VERSION "10.7.1"

NS_ :

BS_:

BU_: ADAS_Chassis AVAS DUMMY_ECU EPS IDB_Chassis MRGEN RCU_Chassis SCAM SRR VCU_Chassis XGW_Chassis YSS

BO_ 1039 YSS_WarnMsg: 8 YSS
 SG_ CHSKM_YSS_WarnMsg : 7|8@0+ (1,0) [0|255] ""  XGW_Chassis
 SG_ ALV_YSS_WarnMsg : 11|4@0+ (1,0) [0|14] ""  XGW_Chassis
 SG_ YSS_Warning_Flag_1 : 12|1@0+ (1,0) [0|1] ""  XGW_Chassis
 SG_ YSS_Warning_Flag_2 : 13|1@0+ (1,0) [0|1] ""  XGW_Chassis
 SG_ YSS_Warning_Flag_3 : 14|1@0+ (1,0) [0|1] ""  XGW_Chassis
 SG_ YSS_Warning_Flag_4 : 15|1@0+ (1,0) [0|1] ""  XGW_Chassis
 SG_ YSS_Warning_Flag_5 : 16|1@0+ (1,0) [0|1] ""  XGW_Chassis
 SG_ YSS_Warning_Flag_6 : 17|1@0+ (1,0) [0|1] ""  XGW_Chassis
 SG_ YSS_Warning_Flag_7 : 18|1@0+ (1,0) [0|1] ""  XGW_Chassis
 SG_ YSS_Warning_Flag_8 : 19|1@0+ (1,0) [0|1] ""  XGW_Chassis
 SG_ YSS_Warning_Flag_9 : 20|1@0+ (1,0) [0|1] ""  XGW_Chassis
 SG_ YSS_Warning_Flag_10 : 21|1@0+ (1,0) [0|1] ""  XGW_Chassis
 SG_ YSS_Warning_Flag_11 : 22|1@0+ (1,0) [0|1] ""  XGW_Chassis
 SG_ YSS_Warning_Flag_12 : 23|1@0+ (1,0) [0|1] ""  XGW_Chassis
 SG_ YSS_Reserved_signal1 : 31|8@0+ (1,0) [0|255] ""  XGW_Chassis
 SG_ YSS_Reserved_signal2 : 39|8@0+ (1,0) [0|255] ""  XGW_Chassis
 SG_ YSS_Reserved_signal3 : 47|8@0+ (1,0) [0|255] ""  XGW_Chassis
 SG_ YSS_Reserved_signal4 : 55|8@0+ (1,0) [0|255] ""  XGW_Chassis
 SG_ YSS_Reserved_signal5 : 63|8@0+ (1,0) [0|255] ""  XGW_Chassis

BO_ 1059 AVAS_STATUS: 8 AVAS
 SG_ AVAS_BatteryUnderVoltage : 0|1@0+ (1,0) [0|1] "-"  VCU_Chassis,XGW_Chassis
 SG_ AVAS_BatteryOverVoltage : 1|1@0+ (1,0) [0|1] "-"  VCU_Chassis,XGW_Chassis
 SG_ AVAS_VINInfoNotPrgm : 2|1@0+ (1,0) [0|1] ""  VCU_Chassis,XGW_Chassis
 SG_ AVAS_AMPVoltSplDrvOperationFail : 3|1@0+ (1,0) [0|1] "-"  VCU_Chassis,XGW_Chassis
 SG_ AVAS_AMPIntFaultOverCurr : 4|1@0+ (1,0) [0|1] ""  VCU_Chassis,XGW_Chassis
 SG_ AVAS_AMPInternalFaultDCError : 5|1@0+ (1,0) [0|1] ""  VCU_Chassis,XGW_Chassis
 SG_ AVAS_AMPInternalFaultOverTemp : 6|1@0+ (1,0) [0|1] ""  VCU_Chassis,XGW_Chassis
 SG_ AVAS_AMPInternalFaultClockError : 7|1@0+ (1,0) [0|1] "-"  VCU_Chassis,XGW_Chassis
 SG_ AVAS_SpkrMntPwrSwDrvHighFlt : 8|1@0+ (1,0) [0|1] "-"  VCU_Chassis,XGW_Chassis
 SG_ AVAS_SpkrMntPwrSwDrvLowFlt : 9|1@0+ (1,0) [0|1] "-"  VCU_Chassis,XGW_Chassis
 SG_ AVAS_InternalSpeakerOpen : 10|1@0+ (1,0) [0|1] ""  VCU_Chassis,XGW_Chassis
 SG_ AVAS_ECUMalFlshOperationErr : 11|1@0+ (1,0) [0|1] ""  VCU_Chassis,XGW_Chassis
 SG_ AVAS_ECUMalfunctionRamFailure : 12|1@0+ (1,0) [0|1] "-"  VCU_Chassis,XGW_Chassis
 SG_ AVAS_ECUMalEEPROMFailure : 13|1@0+ (1,0) [0|1] ""  VCU_Chassis,XGW_Chassis
 SG_ AVAS_CANBusOff : 14|1@0+ (1,0) [0|1] "-"  VCU_Chassis,XGW_Chassis
 SG_ AVAS_LossCommVehicleSpeed : 15|1@0+ (1,0) [0|1] ""  VCU_Chassis,XGW_Chassis
 SG_ AVAS_LossCommGearPosition : 16|1@0+ (1,0) [0|1] "-"  VCU_Chassis,XGW_Chassis
 SG_ AVAS_LossCommAVASCloseCmd : 17|1@0+ (1,0) [0|1] "-"  VCU_Chassis,XGW_Chassis

BO_ 1060 AVAS_SHMNumber: 8 AVAS
 SG_ AVAS_SWNumber : 7|16@0+ (1,0) [0|65535] ""  VCU_Chassis
 SG_ AVAS_HWNumber : 23|16@0+ (1,0) [0|65535] ""  VCU_Chassis
 SG_ AVAS_MXNumber : 39|16@0+ (1,0) [0|65535] ""  VCU_Chassis

BO_ 1061 VCU_AVAS_GearPosition_ECU: 8 VCU_Chassis
 SG_ ActualGearShiftPosition : 50|3@0+ (1,0) [0|7] ""  AVAS,EPS

BO_ 1062 VCU_AVAS_VehicleSpeed_ECU: 8 VCU_Chassis
 SG_ ESP_VehicleSpeed : 4|13@0+ (0.05625,0) [0|460.6875] "kph"  AVAS
 SG_ VCU_STAT_Terminal_BEV : 23|3@0+ (1,0) [0|7] ""  AVAS

BO_ 1063 VCU_AVAS_Close_Cmd: 8 VCU_Chassis
 SG_ IPC_AVASCloseCmd : 0|1@0+ (1,0) [0|1] ""  AVAS

BO_ 1064 XGW_CH_1: 1 XGW_Chassis
 SG_ BCM_Keyfob_Leftcar : 0|1@0+ (1,0) [0|1] ""  VCU_Chassis
 SG_ TRMFitted : 2|2@0+ (1,0) [0|3] ""  ADAS_Chassis

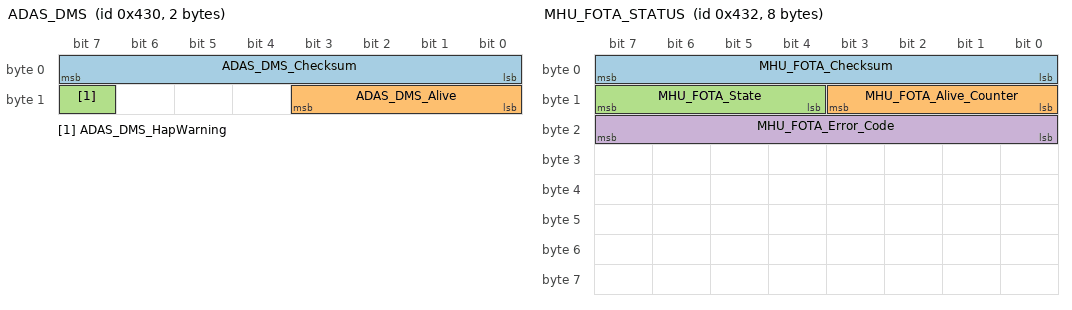
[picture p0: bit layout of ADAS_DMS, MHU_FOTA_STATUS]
BO_ 1072 ADAS_DMS: 2 ADAS_Chassis
 SG_ ADAS_DMS_Checksum : 7|8@0+ (1,0) [0|255] ""  EPS
 SG_ ADAS_DMS_Alive : 11|4@0+ (1,0) [0|14] ""  EPS
 SG_ ADAS_DMS_HapWarning : 15|1@0+ (1,0) [0|1] ""  EPS

BO_ 1074 MHU_FOTA_STATUS: 8 XGW_Chassis
 SG_ MHU_FOTA_Checksum : 7|8@0+ (1,0) [0|255] ""  ADAS_Chassis,EPS,MRGEN,SCAM,SRR
 SG_ MHU_FOTA_Alive_Counter : 11|4@0+ (1,0) [0|14] ""  ADAS_Chassis,EPS,MRGEN,SCAM,SRR
 SG_ MHU_FOTA_State : 15|4@0+ (1,0) [0|14] "-"  ADAS_Chassis,EPS,MRGEN,SCAM,SRR
 SG_ MHU_FOTA_Error_Code : 23|8@0+ (1,0) [0|255] "-"  ADAS_Chassis,EPS,MRGEN,SCAM,SRR

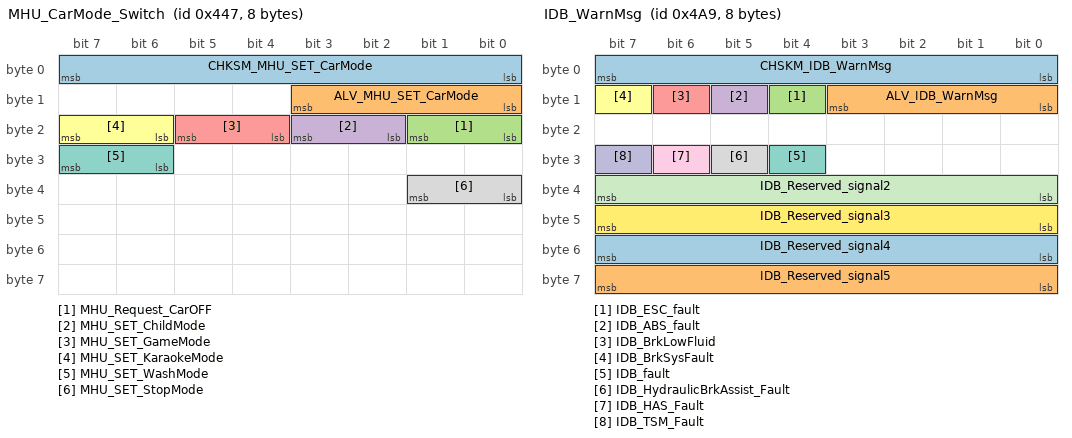
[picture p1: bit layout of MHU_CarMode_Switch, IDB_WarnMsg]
BO_ 1095 MHU_CarMode_Switch: 8 XGW_Chassis
 SG_ CHKSM_MHU_SET_CarMode : 7|8@0+ (1,0) [0|255] ""  IDB_Chassis,RCU_Chassis
 SG_ ALV_MHU_SET_CarMode : 11|4@0+ (1,0) [0|14] ""  IDB_Chassis,RCU_Chassis
 SG_ MHU_Request_CarOFF : 17|2@0+ (1,0) [0|3] "-"  IDB_Chassis,RCU_Chassis
 SG_ MHU_SET_ChildMode : 19|2@0+ (1,0) [0|3] ""  IDB_Chassis,RCU_Chassis
 SG_ MHU_SET_GameMode : 21|2@0+ (1,0) [0|3] ""  IDB_Chassis,RCU_Chassis
 SG_ MHU_SET_KaraokeMode : 23|2@0+ (1,0) [0|3] ""  IDB_Chassis,RCU_Chassis
 SG_ MHU_SET_WashMode : 31|2@0+ (1,0) [0|3] ""  IDB_Chassis,RCU_Chassis
 SG_ MHU_SET_StopMode : 33|2@0+ (1,0) [0|3] ""  IDB_Chassis,RCU_Chassis

BO_ 1191 RCU_WarnMsg: 8 RCU_Chassis
 SG_ CHSKM_RCU_WarnMsg : 7|8@0+ (1,0) [0|255] ""  XGW_Chassis
 SG_ ALV_RCU_WarnMsg : 11|4@0+ (1,0) [0|14] ""  XGW_Chassis
 SG_ RCU_DAA_NoOpDoorOpen : 12|1@0+ (1,0) [0|1] ""  XGW_Chassis
 SG_ RCU_EHandBrk_fault : 13|1@0+ (1,0) [0|1] ""  XGW_Chassis
 SG_ RCU_EOL_NotDone : 14|1@0+ (1,0) [0|1] ""  XGW_Chassis
 SG_ RCU_ECD_RWU_active : 15|1@0+ (1,0) [0|1] ""  XGW_Chassis
 SG_ RCU_ParkOnSteepInclination : 16|1@0+ (1,0) [0|1] ""  XGW_Chassis
 SG_ RCU_BrkForceNotEnough : 17|1@0+ (1,0) [0|1] ""  XGW_Chassis
 SG_ RCU_ReleaseEPB_Wo_PressBrk : 20|1@0+ (1,0) [0|1] ""  XGW_Chassis
 SG_ RCU_ParkBrkApplied : 21|1@0+ (1,0) [0|1] ""  XGW_Chassis
 SG_ RCU_Swch_Mafnc : 27|1@0+ (1,0) [0|1] ""  XGW_Chassis
 SG_ RCU_DAA_NoOpBeltUnbuckled : 28|1@0+ (1,0) [0|1] ""  XGW_Chassis
 SG_ RCU_RollerBenchMode : 29|1@0+ (1,0) [0|1] ""  XGW_Chassis
 SG_ RCU_EPB_ParkLampState : 31|2@0+ (1,0) [0|3] ""  XGW_Chassis
 SG_ RCU_EPB_WarnLampState : 34|2@0+ (1,0) [0|3] ""  XGW_Chassis
 SG_ RCU_WflagRes36 : 36|1@0+ (1,0) [0|1] ""  XGW_Chassis
 SG_ RCU_WflagRes37 : 37|1@0+ (1,0) [0|1] ""  XGW_Chassis
 SG_ RCU_WflagRes38 : 38|1@0+ (1,0) [0|1] ""  XGW_Chassis
 SG_ RCU_WflagRes39 : 39|1@0+ (1,0) [0|1] ""  XGW_Chassis
 SG_ RCU_WflagRes40 : 40|1@0+ (1,0) [0|1] ""  XGW_Chassis
 SG_ RCU_WflagRes41 : 41|1@0+ (1,0) [0|1] ""  XGW_Chassis
 SG_ RCU_WflagRes42 : 42|1@0+ (1,0) [0|1] ""  XGW_Chassis
 SG_ RCU_WflagRes43 : 43|1@0+ (1,0) [0|1] ""  XGW_Chassis
 SG_ RCU_WflagRes44 : 44|1@0+ (1,0) [0|1] ""  XGW_Chassis
 SG_ RCU_WflagRes45 : 45|1@0+ (1,0) [0|1] ""  XGW_Chassis
 SG_ RCU_WflagRes46 : 46|1@0+ (1,0) [0|1] ""  XGW_Chassis
 SG_ RCU_WflagRes47 : 47|1@0+ (1,0) [0|1] ""  XGW_Chassis
 SG_ RCU_Reserved_signal1 : 55|8@0+ (1,0) [0|255] ""  XGW_Chassis

BO_ 1192 EPS_WarnMsg: 8 EPS
 SG_ CHSKM_EPS_WarnMsg : 7|8@0+ (1,0) [0|255] ""  XGW_Chassis
 SG_ ALV_EPS_WarnMsg : 11|4@0+ (1,0) [0|14] ""  XGW_Chassis
 SG_ EPS_Malfunction : 12|1@0+ (1,0) [0|1] "-"  XGW_Chassis
 SG_ EPS_Reduced : 13|1@0+ (1,0) [0|1] "-"  XGW_Chassis
 SG_ EPS_Overheat : 14|1@0+ (1,0) [0|1] ""  XGW_Chassis
 SG_ EPS_NotReady : 15|1@0+ (1,0) [0|1] "-"  XGW_Chassis
 SG_ EPS_Warning_Flag_5 : 16|1@0+ (1,0) [0|1] "-"  XGW_Chassis
 SG_ EPS_Warning_Flag_6 : 17|1@0+ (1,0) [0|1] ""  XGW_Chassis
 SG_ EPS_Warning_Flag_7 : 18|1@0+ (1,0) [0|1] ""  XGW_Chassis
 SG_ EPS_Warning_Flag_8 : 19|1@0+ (1,0) [0|1] "-"  XGW_Chassis
 SG_ EPS_Warning_Flag_9 : 20|1@0+ (1,0) [0|1] "-"  XGW_Chassis
 SG_ EPS_Warning_Flag_10 : 21|1@0+ (1,0) [0|1] ""  XGW_Chassis
 SG_ EPS_Warning_Flag_11 : 22|1@0+ (1,0) [0|1] ""  XGW_Chassis
 SG_ EPS_Warning_Flag_12 : 23|1@0+ (1,0) [0|1] "-"  XGW_Chassis
 SG_ EPS_Reserved_signal1 : 31|8@0+ (1,0) [0|255] ""  XGW_Chassis
 SG_ EPS_Reserved_signal2 : 39|8@0+ (1,0) [0|255] ""  XGW_Chassis
 SG_ EPS_Reserved_signal3 : 47|8@0+ (1,0) [0|255] "-"  XGW_Chassis
 SG_ EPS_Reserved_signal4 : 55|8@0+ (1,0) [0|255] ""  XGW_Chassis
 SG_ EPS_Reserved_signal5 : 63|8@0+ (1,0) [0|255] ""  XGW_Chassis

BO_ 1193 IDB_WarnMsg: 8 IDB_Chassis
 SG_ CHSKM_IDB_WarnMsg : 7|8@0+ (1,0) [0|255] ""  XGW_Chassis
 SG_ ALV_IDB_WarnMsg : 11|4@0+ (1,0) [0|14] ""  XGW_Chassis
 SG_ IDB_ESC_fault : 12|1@0+ (1,0) [0|1] "-"  XGW_Chassis
 SG_ IDB_ABS_fault : 13|1@0+ (1,0) [0|1] ""  XGW_Chassis
 SG_ IDB_BrkLowFluid : 14|1@0+ (1,0) [0|1] ""  XGW_Chassis
 SG_ IDB_BrkSysFault : 15|1@0+ (1,0) [0|1] "-"  XGW_Chassis
 SG_ IDB_fault : 28|1@0+ (1,0) [0|1] ""  SCAM,XGW_Chassis
 SG_ IDB_HydraulicBrkAssist_Fault : 29|1@0+ (1,0) [0|1] "-"  XGW_Chassis
 SG_ IDB_HAS_Fault : 30|1@0+ (1,0) [0|1] ""  XGW_Chassis
 SG_ IDB_TSM_Fault : 31|1@0+ (1,0) [0|1] ""  XGW_Chassis
 SG_ IDB_Reserved_signal2 : 39|8@0+ (1,0) [0|255] "-"  XGW_Chassis
 SG_ IDB_Reserved_signal3 : 47|8@0+ (1,0) [0|255] "-"  XGW_Chassis
 SG_ IDB_Reserved_signal4 : 55|8@0+ (1,0) [0|255] "-"  XGW_Chassis
 SG_ IDB_Reserved_signal5 : 63|8@0+ (1,0) [0|255] ""  XGW_Chassis

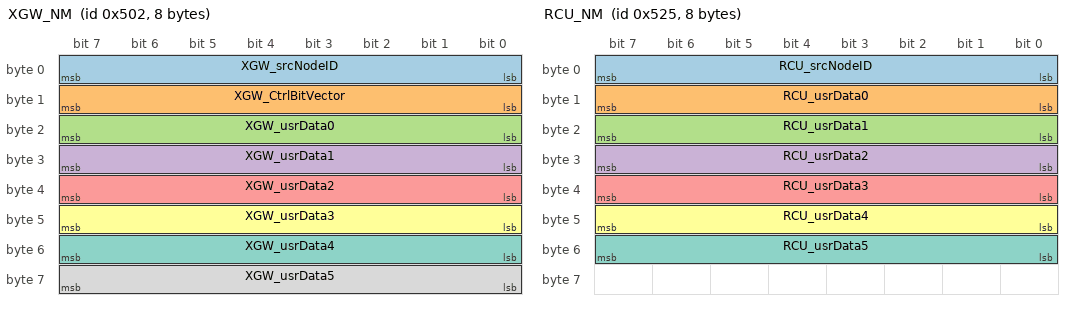
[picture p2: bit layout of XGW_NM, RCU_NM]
BO_ 1282 XGW_NM: 8 XGW_Chassis
 SG_ XGW_srcNodeID : 7|8@0+ (1,0) [0|255] ""  ADAS_Chassis,IDB_Chassis,MRGEN,RCU_Chassis,SCAM,VCU_Chassis
 SG_ XGW_CtrlBitVector : 15|8@0+ (1,0) [0|255] ""  ADAS_Chassis,IDB_Chassis,MRGEN,RCU_Chassis,SCAM,VCU_Chassis
 SG_ XGW_usrData0 : 23|8@0+ (1,0) [0|255] ""  ADAS_Chassis,IDB_Chassis,MRGEN,RCU_Chassis,SCAM,VCU_Chassis
 SG_ XGW_usrData1 : 31|8@0+ (1,0) [0|255] ""  ADAS_Chassis,IDB_Chassis,MRGEN,RCU_Chassis,SCAM,VCU_Chassis
 SG_ XGW_usrData2 : 39|8@0+ (1,0) [0|255] ""  ADAS_Chassis,IDB_Chassis,MRGEN,RCU_Chassis,SCAM,VCU_Chassis
 SG_ XGW_usrData3 : 47|8@0+ (1,0) [0|255] ""  ADAS_Chassis,IDB_Chassis,MRGEN,RCU_Chassis,SCAM,VCU_Chassis
 SG_ XGW_usrData4 : 55|8@0+ (1,0) [0|255] ""  ADAS_Chassis,IDB_Chassis,MRGEN,RCU_Chassis,SCAM,VCU_Chassis
 SG_ XGW_usrData5 : 63|8@0+ (1,0) [0|255] ""  ADAS_Chassis,IDB_Chassis,MRGEN,RCU_Chassis,SCAM,VCU_Chassis

BO_ 1317 RCU_NM: 8 RCU_Chassis
 SG_ RCU_srcNodeID : 7|8@0+ (1,0) [0|255] ""  ADAS_Chassis,IDB_Chassis,MRGEN,SCAM,VCU_Chassis,XGW_Chassis
 SG_ RCU_usrData0 : 15|8@0+ (1,0) [0|255] ""  ADAS_Chassis,IDB_Chassis,MRGEN,SCAM,VCU_Chassis,XGW_Chassis
 SG_ RCU_usrData1 : 23|8@0+ (1,0) [0|255] ""  ADAS_Chassis,IDB_Chassis,MRGEN,SCAM,VCU_Chassis,XGW_Chassis
 SG_ RCU_usrData2 : 31|8@0+ (1,0) [0|255] ""  ADAS_Chassis,IDB_Chassis,MRGEN,SCAM,VCU_Chassis,XGW_Chassis
 SG_ RCU_usrData3 : 39|8@0+ (1,0) [0|255] ""  ADAS_Chassis,IDB_Chassis,MRGEN,SCAM,VCU_Chassis,XGW_Chassis
 SG_ RCU_usrData4 : 47|8@0+ (1,0) [0|255] ""  ADAS_Chassis,IDB_Chassis,MRGEN,SCAM,VCU_Chassis,XGW_Chassis
 SG_ RCU_usrData5 : 55|8@0+ (1,0) [0|255] ""  ADAS_Chassis,IDB_Chassis,MRGEN,SCAM,VCU_Chassis,XGW_Chassis

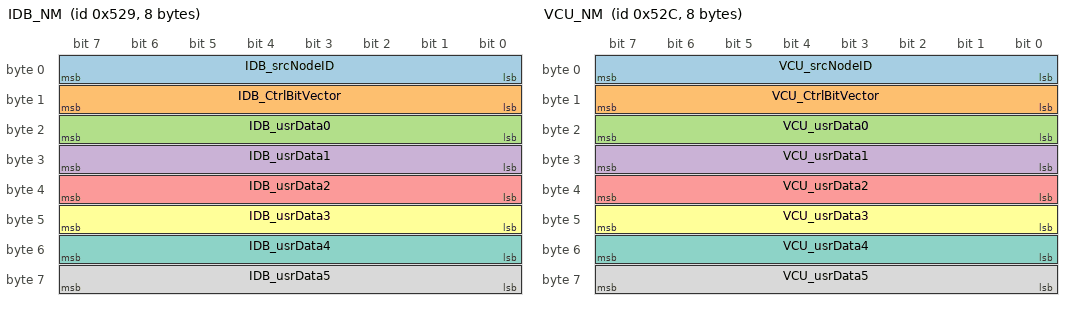
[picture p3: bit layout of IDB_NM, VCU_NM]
BO_ 1321 IDB_NM: 8 IDB_Chassis
 SG_ IDB_srcNodeID : 7|8@0+ (1,0) [0|255] ""  ADAS_Chassis,MRGEN,RCU_Chassis,SCAM,VCU_Chassis,XGW_Chassis
 SG_ IDB_CtrlBitVector : 15|8@0+ (1,0) [0|255] ""  ADAS_Chassis,MRGEN,RCU_Chassis,SCAM,VCU_Chassis,XGW_Chassis
 SG_ IDB_usrData0 : 23|8@0+ (1,0) [0|255] ""  ADAS_Chassis,MRGEN,RCU_Chassis,SCAM,VCU_Chassis,XGW_Chassis
 SG_ IDB_usrData1 : 31|8@0+ (1,0) [0|255] ""  ADAS_Chassis,MRGEN,RCU_Chassis,SCAM,VCU_Chassis,XGW_Chassis
 SG_ IDB_usrData2 : 39|8@0+ (1,0) [0|255] ""  ADAS_Chassis,MRGEN,RCU_Chassis,SCAM,VCU_Chassis,XGW_Chassis
 SG_ IDB_usrData3 : 47|8@0+ (1,0) [0|255] ""  ADAS_Chassis,MRGEN,RCU_Chassis,SCAM,VCU_Chassis,XGW_Chassis
 SG_ IDB_usrData4 : 55|8@0+ (1,0) [0|255] ""  ADAS_Chassis,MRGEN,RCU_Chassis,SCAM,VCU_Chassis,XGW_Chassis
 SG_ IDB_usrData5 : 63|8@0+ (1,0) [0|255] ""  ADAS_Chassis,MRGEN,RCU_Chassis,SCAM,VCU_Chassis,XGW_Chassis

BO_ 1324 VCU_NM: 8 VCU_Chassis
 SG_ VCU_srcNodeID : 7|8@0+ (1,0) [0|255] ""  ADAS_Chassis,IDB_Chassis,MRGEN,RCU_Chassis,SCAM,SRR,XGW_Chassis
 SG_ VCU_CtrlBitVector : 15|8@0+ (1,0) [0|255] ""  ADAS_Chassis,IDB_Chassis,MRGEN,RCU_Chassis,SCAM,SRR,XGW_Chassis
 SG_ VCU_usrData0 : 23|8@0+ (1,0) [0|255] ""  ADAS_Chassis,IDB_Chassis,MRGEN,RCU_Chassis,SCAM,SRR,XGW_Chassis
 SG_ VCU_usrData1 : 31|8@0+ (1,0) [0|255] ""  ADAS_Chassis,IDB_Chassis,MRGEN,RCU_Chassis,SCAM,SRR,XGW_Chassis
 SG_ VCU_usrData2 : 39|8@0+ (1,0) [0|255] ""  ADAS_Chassis,IDB_Chassis,MRGEN,RCU_Chassis,SCAM,SRR,XGW_Chassis
 SG_ VCU_usrData3 : 47|8@0+ (1,0) [0|255] ""  ADAS_Chassis,IDB_Chassis,MRGEN,RCU_Chassis,SCAM,SRR,XGW_Chassis
 SG_ VCU_usrData4 : 55|8@0+ (1,0) [0|255] ""  ADAS_Chassis,IDB_Chassis,MRGEN,RCU_Chassis,SCAM,SRR,XGW_Chassis
 SG_ VCU_usrData5 : 63|8@0+ (1,0) [0|255] ""  ADAS_Chassis,IDB_Chassis,MRGEN,RCU_Chassis,SCAM,SRR,XGW_Chassis

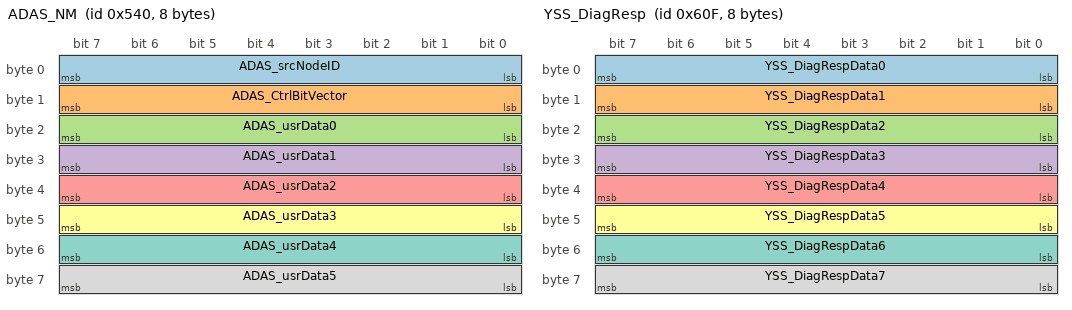
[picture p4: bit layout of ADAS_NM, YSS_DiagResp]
BO_ 1344 ADAS_NM: 8 ADAS_Chassis
 SG_ ADAS_srcNodeID : 7|8@0+ (1,0) [0|255] ""  IDB_Chassis,RCU_Chassis,VCU_Chassis,XGW_Chassis
 SG_ ADAS_CtrlBitVector : 15|8@0+ (1,0) [0|255] "-"  IDB_Chassis,RCU_Chassis,VCU_Chassis,XGW_Chassis
 SG_ ADAS_usrData0 : 23|8@0+ (1,0) [0|255] ""  IDB_Chassis,RCU_Chassis,VCU_Chassis,XGW_Chassis
 SG_ ADAS_usrData1 : 31|8@0+ (1,0) [0|255] ""  IDB_Chassis,RCU_Chassis,VCU_Chassis,XGW_Chassis
 SG_ ADAS_usrData2 : 39|8@0+ (1,0) [0|255] ""  IDB_Chassis,RCU_Chassis,VCU_Chassis,XGW_Chassis
 SG_ ADAS_usrData3 : 47|8@0+ (1,0) [0|255] "-"  IDB_Chassis,RCU_Chassis,VCU_Chassis,XGW_Chassis
 SG_ ADAS_usrData4 : 55|8@0+ (1,0) [0|255] "-"  IDB_Chassis,RCU_Chassis,VCU_Chassis,XGW_Chassis
 SG_ ADAS_usrData5 : 63|8@0+ (1,0) [0|255] "-"  IDB_Chassis,RCU_Chassis,VCU_Chassis,XGW_Chassis

BO_ 1551 YSS_DiagResp: 8 YSS
 SG_ YSS_DiagRespData0 : 7|8@0+ (1,0) [0|255] ""  XGW_Chassis
 SG_ YSS_DiagRespData1 : 15|8@0+ (1,0) [0|255] ""  XGW_Chassis
 SG_ YSS_DiagRespData2 : 23|8@0+ (1,0) [0|255] "-"  XGW_Chassis
 SG_ YSS_DiagRespData3 : 31|8@0+ (1,0) [0|255] ""  XGW_Chassis
 SG_ YSS_DiagRespData4 : 39|8@0+ (1,0) [0|255] ""  XGW_Chassis
 SG_ YSS_DiagRespData5 : 47|8@0+ (1,0) [0|255] ""  XGW_Chassis
 SG_ YSS_DiagRespData6 : 55|8@0+ (1,0) [0|255] ""  XGW_Chassis
 SG_ YSS_DiagRespData7 : 63|8@0+ (1,0) [0|255] ""  XGW_Chassis

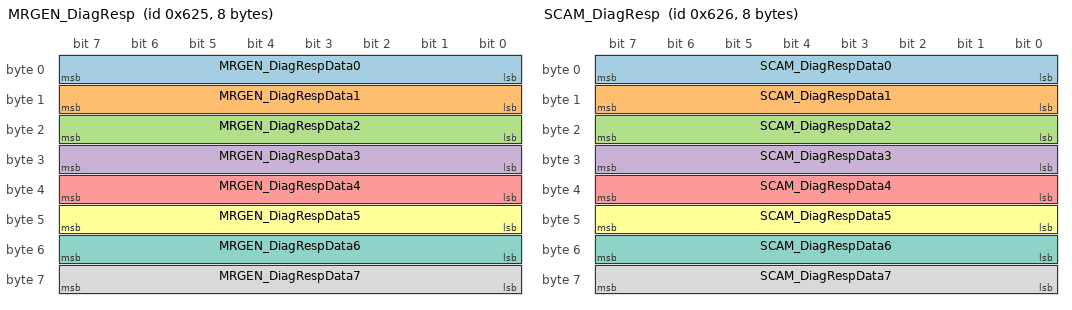
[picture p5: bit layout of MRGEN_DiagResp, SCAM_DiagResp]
BO_ 1573 MRGEN_DiagResp: 8 MRGEN
 SG_ MRGEN_DiagRespData0 : 7|8@0+ (1,0) [0|255] ""  XGW_Chassis
 SG_ MRGEN_DiagRespData1 : 15|8@0+ (1,0) [0|255] "-"  XGW_Chassis
 SG_ MRGEN_DiagRespData2 : 23|8@0+ (1,0) [0|255] ""  XGW_Chassis
 SG_ MRGEN_DiagRespData3 : 31|8@0+ (1,0) [0|255] ""  XGW_Chassis
 SG_ MRGEN_DiagRespData4 : 39|8@0+ (1,0) [0|255] ""  XGW_Chassis
 SG_ MRGEN_DiagRespData5 : 47|8@0+ (1,0) [0|255] ""  XGW_Chassis
 SG_ MRGEN_DiagRespData6 : 55|8@0+ (1,0) [0|255] ""  XGW_Chassis
 SG_ MRGEN_DiagRespData7 : 63|8@0+ (1,0) [0|255] "-"  XGW_Chassis

BO_ 1574 SCAM_DiagResp: 8 SCAM
 SG_ SCAM_DiagRespData0 : 7|8@0+ (1,0) [0|255] ""  XGW_Chassis
 SG_ SCAM_DiagRespData1 : 15|8@0+ (1,0) [0|255] ""  XGW_Chassis
 SG_ SCAM_DiagRespData2 : 23|8@0+ (1,0) [0|255] ""  XGW_Chassis
 SG_ SCAM_DiagRespData3 : 31|8@0+ (1,0) [0|255] ""  XGW_Chassis
 SG_ SCAM_DiagRespData4 : 39|8@0+ (1,0) [0|255] ""  XGW_Chassis
 SG_ SCAM_DiagRespData5 : 47|8@0+ (1,0) [0|255] "-"  XGW_Chassis
 SG_ SCAM_DiagRespData6 : 55|8@0+ (1,0) [0|255] ""  XGW_Chassis
 SG_ SCAM_DiagRespData7 : 63|8@0+ (1,0) [0|255] ""  XGW_Chassis

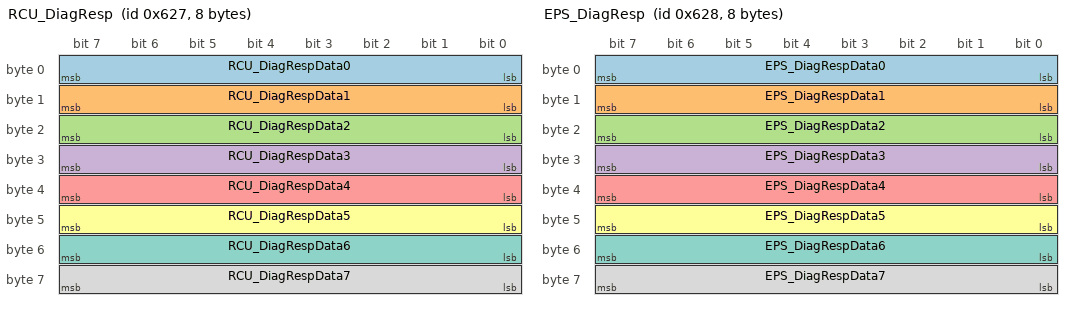
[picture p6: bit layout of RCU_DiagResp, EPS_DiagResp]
BO_ 1575 RCU_DiagResp: 8 RCU_Chassis
 SG_ RCU_DiagRespData0 : 7|8@0+ (1,0) [0|255] ""  XGW_Chassis
 SG_ RCU_DiagRespData1 : 15|8@0+ (1,0) [0|255] ""  XGW_Chassis
 SG_ RCU_DiagRespData2 : 23|8@0+ (1,0) [0|255] ""  XGW_Chassis
 SG_ RCU_DiagRespData3 : 31|8@0+ (1,0) [0|255] ""  XGW_Chassis
 SG_ RCU_DiagRespData4 : 39|8@0+ (1,0) [0|255] ""  XGW_Chassis
 SG_ RCU_DiagRespData5 : 47|8@0+ (1,0) [0|255] ""  XGW_Chassis
 SG_ RCU_DiagRespData6 : 55|8@0+ (1,0) [0|255] ""  XGW_Chassis
 SG_ RCU_DiagRespData7 : 63|8@0+ (1,0) [0|255] ""  XGW_Chassis

BO_ 1576 EPS_DiagResp: 8 EPS
 SG_ EPS_DiagRespData0 : 7|8@0+ (1,0) [0|255] "-"  XGW_Chassis
 SG_ EPS_DiagRespData1 : 15|8@0+ (1,0) [0|255] ""  XGW_Chassis
 SG_ EPS_DiagRespData2 : 23|8@0+ (1,0) [0|255] ""  XGW_Chassis
 SG_ EPS_DiagRespData3 : 31|8@0+ (1,0) [0|255] "-"  XGW_Chassis
 SG_ EPS_DiagRespData4 : 39|8@0+ (1,0) [0|255] ""  XGW_Chassis
 SG_ EPS_DiagRespData5 : 47|8@0+ (1,0) [0|255] ""  XGW_Chassis
 SG_ EPS_DiagRespData6 : 55|8@0+ (1,0) [0|255] "-"  XGW_Chassis
 SG_ EPS_DiagRespData7 : 63|8@0+ (1,0) [0|255] "-"  XGW_Chassis

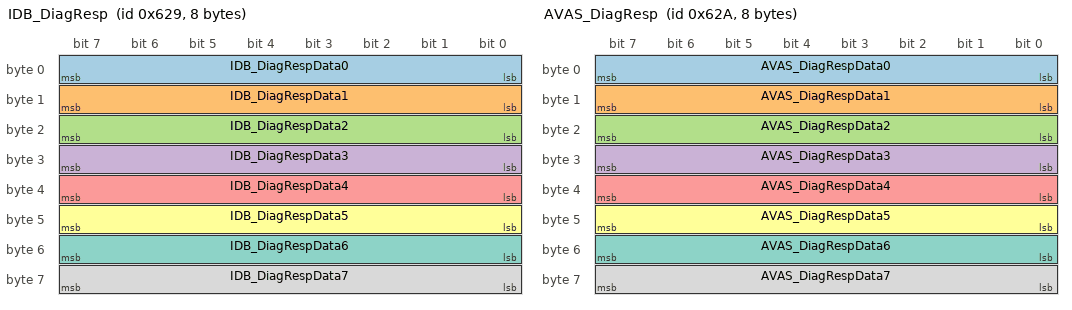
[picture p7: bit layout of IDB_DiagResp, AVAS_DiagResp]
BO_ 1577 IDB_DiagResp: 8 IDB_Chassis
 SG_ IDB_DiagRespData0 : 7|8@0+ (1,0) [0|255] ""  XGW_Chassis
 SG_ IDB_DiagRespData1 : 15|8@0+ (1,0) [0|255] "-"  XGW_Chassis
 SG_ IDB_DiagRespData2 : 23|8@0+ (1,0) [0|255] "-"  XGW_Chassis
 SG_ IDB_DiagRespData3 : 31|8@0+ (1,0) [0|255] ""  XGW_Chassis
 SG_ IDB_DiagRespData4 : 39|8@0+ (1,0) [0|255] ""  XGW_Chassis
 SG_ IDB_DiagRespData5 : 47|8@0+ (1,0) [0|255] "-"  XGW_Chassis
 SG_ IDB_DiagRespData6 : 55|8@0+ (1,0) [0|255] "-"  XGW_Chassis
 SG_ IDB_DiagRespData7 : 63|8@0+ (1,0) [0|255] ""  XGW_Chassis

BO_ 1578 AVAS_DiagResp: 8 AVAS
 SG_ AVAS_DiagRespData0 : 7|8@0+ (1,0) [0|255] ""  XGW_Chassis
 SG_ AVAS_DiagRespData1 : 15|8@0+ (1,0) [0|255] ""  XGW_Chassis
 SG_ AVAS_DiagRespData2 : 23|8@0+ (1,0) [0|255] ""  XGW_Chassis
 SG_ AVAS_DiagRespData3 : 31|8@0+ (1,0) [0|255] ""  XGW_Chassis
 SG_ AVAS_DiagRespData4 : 39|8@0+ (1,0) [0|255] ""  XGW_Chassis
 SG_ AVAS_DiagRespData5 : 47|8@0+ (1,0) [0|255] ""  XGW_Chassis
 SG_ AVAS_DiagRespData6 : 55|8@0+ (1,0) [0|255] ""  XGW_Chassis
 SG_ AVAS_DiagRespData7 : 63|8@0+ (1,0) [0|255] "-"  XGW_Chassis

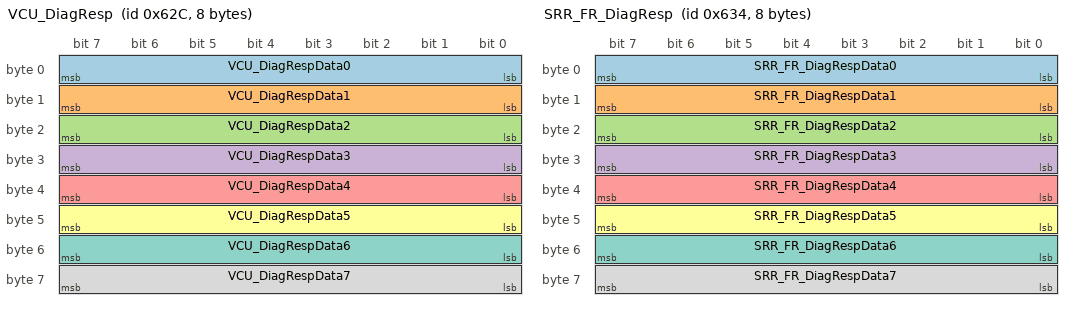
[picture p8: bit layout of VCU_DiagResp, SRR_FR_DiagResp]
BO_ 1580 VCU_DiagResp: 8 VCU_Chassis
 SG_ VCU_DiagRespData0 : 7|8@0+ (1,0) [0|255] ""  XGW_Chassis
 SG_ VCU_DiagRespData1 : 15|8@0+ (1,0) [0|255] ""  XGW_Chassis
 SG_ VCU_DiagRespData2 : 23|8@0+ (1,0) [0|255] ""  XGW_Chassis
 SG_ VCU_DiagRespData3 : 31|8@0+ (1,0) [0|255] ""  XGW_Chassis
 SG_ VCU_DiagRespData4 : 39|8@0+ (1,0) [0|255] "-"  XGW_Chassis
 SG_ VCU_DiagRespData5 : 47|8@0+ (1,0) [0|255] ""  XGW_Chassis
 SG_ VCU_DiagRespData6 : 55|8@0+ (1,0) [0|255] ""  XGW_Chassis
 SG_ VCU_DiagRespData7 : 63|8@0+ (1,0) [0|255] "-"  XGW_Chassis

BO_ 1588 SRR_FR_DiagResp: 8 ADAS_Chassis
 SG_ SRR_FR_DiagRespData0 : 7|8@0+ (1,0) [0|255] "-"  XGW_Chassis
 SG_ SRR_FR_DiagRespData1 : 15|8@0+ (1,0) [0|255] "-"  XGW_Chassis
 SG_ SRR_FR_DiagRespData2 : 23|8@0+ (1,0) [0|255] "-"  XGW_Chassis
 SG_ SRR_FR_DiagRespData3 : 31|8@0+ (1,0) [0|255] ""  XGW_Chassis
 SG_ SRR_FR_DiagRespData4 : 39|8@0+ (1,0) [0|255] ""  XGW_Chassis
 SG_ SRR_FR_DiagRespData5 : 47|8@0+ (1,0) [0|255] ""  XGW_Chassis
 SG_ SRR_FR_DiagRespData6 : 55|8@0+ (1,0) [0|255] ""  XGW_Chassis
 SG_ SRR_FR_DiagRespData7 : 63|8@0+ (1,0) [0|255] ""  XGW_Chassis

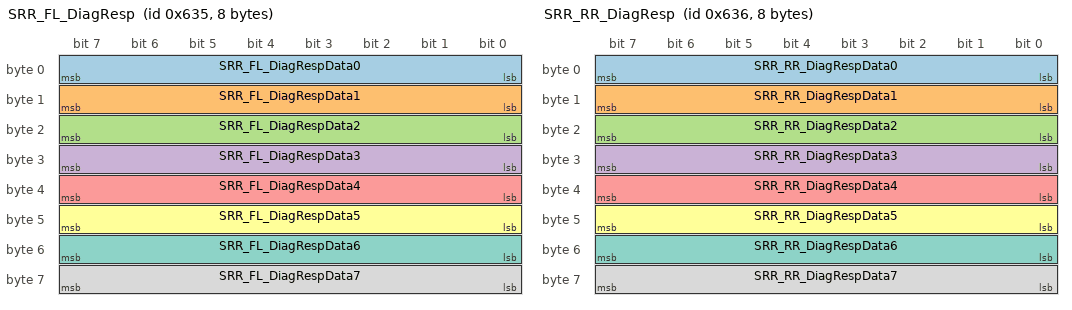
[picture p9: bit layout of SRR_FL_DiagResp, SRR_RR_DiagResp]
BO_ 1589 SRR_FL_DiagResp: 8 ADAS_Chassis
 SG_ SRR_FL_DiagRespData0 : 7|8@0+ (1,0) [0|255] ""  XGW_Chassis
 SG_ SRR_FL_DiagRespData1 : 15|8@0+ (1,0) [0|255] "-"  XGW_Chassis
 SG_ SRR_FL_DiagRespData2 : 23|8@0+ (1,0) [0|255] ""  XGW_Chassis
 SG_ SRR_FL_DiagRespData3 : 31|8@0+ (1,0) [0|255] "-"  XGW_Chassis
 SG_ SRR_FL_DiagRespData4 : 39|8@0+ (1,0) [0|255] ""  XGW_Chassis
 SG_ SRR_FL_DiagRespData5 : 47|8@0+ (1,0) [0|255] "-"  XGW_Chassis
 SG_ SRR_FL_DiagRespData6 : 55|8@0+ (1,0) [0|255] "-"  XGW_Chassis
 SG_ SRR_FL_DiagRespData7 : 63|8@0+ (1,0) [0|255] ""  XGW_Chassis

BO_ 1590 SRR_RR_DiagResp: 8 ADAS_Chassis
 SG_ SRR_RR_DiagRespData0 : 7|8@0+ (1,0) [0|255] ""  XGW_Chassis
 SG_ SRR_RR_DiagRespData1 : 15|8@0+ (1,0) [0|255] "-"  XGW_Chassis
 SG_ SRR_RR_DiagRespData2 : 23|8@0+ (1,0) [0|255] "-"  XGW_Chassis
 SG_ SRR_RR_DiagRespData3 : 31|8@0+ (1,0) [0|255] ""  XGW_Chassis
 SG_ SRR_RR_DiagRespData4 : 39|8@0+ (1,0) [0|255] "-"  XGW_Chassis
 SG_ SRR_RR_DiagRespData5 : 47|8@0+ (1,0) [0|255] "-"  XGW_Chassis
 SG_ SRR_RR_DiagRespData6 : 55|8@0+ (1,0) [0|255] "-"  XGW_Chassis
 SG_ SRR_RR_DiagRespData7 : 63|8@0+ (1,0) [0|255] "-"  XGW_Chassis

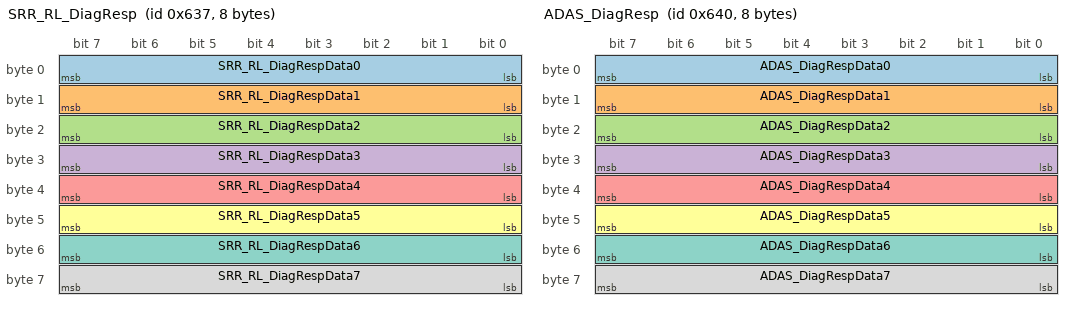
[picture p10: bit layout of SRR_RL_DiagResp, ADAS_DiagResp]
BO_ 1591 SRR_RL_DiagResp: 8 ADAS_Chassis
 SG_ SRR_RL_DiagRespData0 : 7|8@0+ (1,0) [0|255] ""  XGW_Chassis
 SG_ SRR_RL_DiagRespData1 : 15|8@0+ (1,0) [0|255] "-"  XGW_Chassis
 SG_ SRR_RL_DiagRespData2 : 23|8@0+ (1,0) [0|255] "-"  XGW_Chassis
 SG_ SRR_RL_DiagRespData3 : 31|8@0+ (1,0) [0|255] "-"  XGW_Chassis
 SG_ SRR_RL_DiagRespData4 : 39|8@0+ (1,0) [0|255] ""  XGW_Chassis
 SG_ SRR_RL_DiagRespData5 : 47|8@0+ (1,0) [0|255] "-"  XGW_Chassis
 SG_ SRR_RL_DiagRespData6 : 55|8@0+ (1,0) [0|255] "-"  XGW_Chassis
 SG_ SRR_RL_DiagRespData7 : 63|8@0+ (1,0) [0|255] "-"  XGW_Chassis

BO_ 1600 ADAS_DiagResp: 8 ADAS_Chassis
 SG_ ADAS_DiagRespData0 : 7|8@0+ (1,0) [0|255] ""  XGW_Chassis
 SG_ ADAS_DiagRespData1 : 15|8@0+ (1,0) [0|255] ""  XGW_Chassis
 SG_ ADAS_DiagRespData2 : 23|8@0+ (1,0) [0|255] ""  XGW_Chassis
 SG_ ADAS_DiagRespData3 : 31|8@0+ (1,0) [0|255] ""  XGW_Chassis
 SG_ ADAS_DiagRespData4 : 39|8@0+ (1,0) [0|255] ""  XGW_Chassis
 SG_ ADAS_DiagRespData5 : 47|8@0+ (1,0) [0|255] ""  XGW_Chassis
 SG_ ADAS_DiagRespData6 : 55|8@0+ (1,0) [0|255] ""  XGW_Chassis
 SG_ ADAS_DiagRespData7 : 63|8@0+ (1,0) [0|255] ""  XGW_Chassis

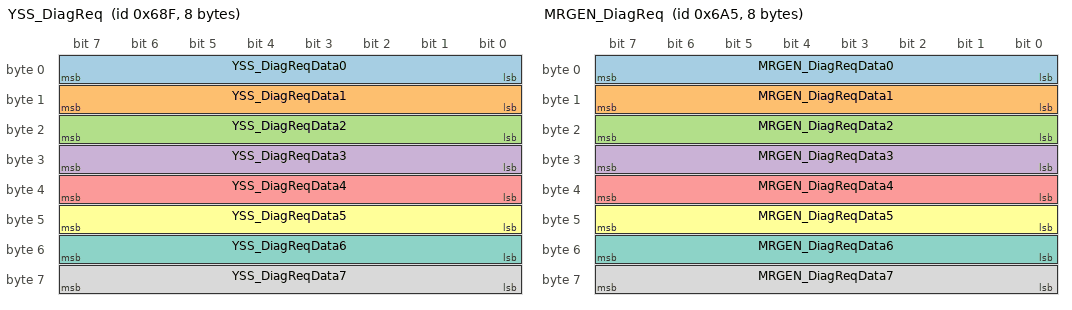
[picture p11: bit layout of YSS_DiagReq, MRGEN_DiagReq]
BO_ 1679 YSS_DiagReq: 8 XGW_Chassis
 SG_ YSS_DiagReqData0 : 7|8@0+ (1,0) [0|255] ""  YSS
 SG_ YSS_DiagReqData1 : 15|8@0+ (1,0) [0|255] ""  YSS
 SG_ YSS_DiagReqData2 : 23|8@0+ (1,0) [0|255] "-"  YSS
 SG_ YSS_DiagReqData3 : 31|8@0+ (1,0) [0|255] "-"  YSS
 SG_ YSS_DiagReqData4 : 39|8@0+ (1,0) [0|255] "-"  YSS
 SG_ YSS_DiagReqData5 : 47|8@0+ (1,0) [0|255] "-"  YSS
 SG_ YSS_DiagReqData6 : 55|8@0+ (1,0) [0|255] ""  YSS
 SG_ YSS_DiagReqData7 : 63|8@0+ (1,0) [0|255] ""  YSS

BO_ 1701 MRGEN_DiagReq: 8 XGW_Chassis
 SG_ MRGEN_DiagReqData0 : 7|8@0+ (1,0) [0|255] ""  MRGEN
 SG_ MRGEN_DiagReqData1 : 15|8@0+ (1,0) [0|255] ""  MRGEN
 SG_ MRGEN_DiagReqData2 : 23|8@0+ (1,0) [0|255] ""  MRGEN
 SG_ MRGEN_DiagReqData3 : 31|8@0+ (1,0) [0|255] ""  MRGEN
 SG_ MRGEN_DiagReqData4 : 39|8@0+ (1,0) [0|255] ""  MRGEN
 SG_ MRGEN_DiagReqData5 : 47|8@0+ (1,0) [0|255] "-"  MRGEN
 SG_ MRGEN_DiagReqData6 : 55|8@0+ (1,0) [0|255] ""  MRGEN
 SG_ MRGEN_DiagReqData7 : 63|8@0+ (1,0) [0|255] ""  MRGEN

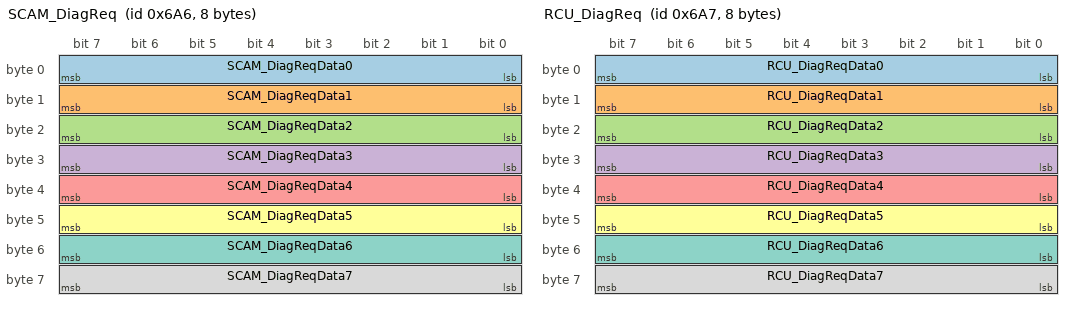
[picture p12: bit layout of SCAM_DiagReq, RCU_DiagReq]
BO_ 1702 SCAM_DiagReq: 8 XGW_Chassis
 SG_ SCAM_DiagReqData0 : 7|8@0+ (1,0) [0|255] "-"  SCAM
 SG_ SCAM_DiagReqData1 : 15|8@0+ (1,0) [0|255] ""  SCAM
 SG_ SCAM_DiagReqData2 : 23|8@0+ (1,0) [0|255] "-"  SCAM
 SG_ SCAM_DiagReqData3 : 31|8@0+ (1,0) [0|255] "-"  SCAM
 SG_ SCAM_DiagReqData4 : 39|8@0+ (1,0) [0|255] ""  SCAM
 SG_ SCAM_DiagReqData5 : 47|8@0+ (1,0) [0|255] "-"  SCAM
 SG_ SCAM_DiagReqData6 : 55|8@0+ (1,0) [0|255] "-"  SCAM
 SG_ SCAM_DiagReqData7 : 63|8@0+ (1,0) [0|255] "-"  SCAM

BO_ 1703 RCU_DiagReq: 8 XGW_Chassis
 SG_ RCU_DiagReqData0 : 7|8@0+ (1,0) [0|255] ""  RCU_Chassis
 SG_ RCU_DiagReqData1 : 15|8@0+ (1,0) [0|255] ""  RCU_Chassis
 SG_ RCU_DiagReqData2 : 23|8@0+ (1,0) [0|255] ""  RCU_Chassis
 SG_ RCU_DiagReqData3 : 31|8@0+ (1,0) [0|255] ""  RCU_Chassis
 SG_ RCU_DiagReqData4 : 39|8@0+ (1,0) [0|255] "-"  RCU_Chassis
 SG_ RCU_DiagReqData5 : 47|8@0+ (1,0) [0|255] ""  RCU_Chassis
 SG_ RCU_DiagReqData6 : 55|8@0+ (1,0) [0|255] "-"  RCU_Chassis
 SG_ RCU_DiagReqData7 : 63|8@0+ (1,0) [0|255] "-"  RCU_Chassis

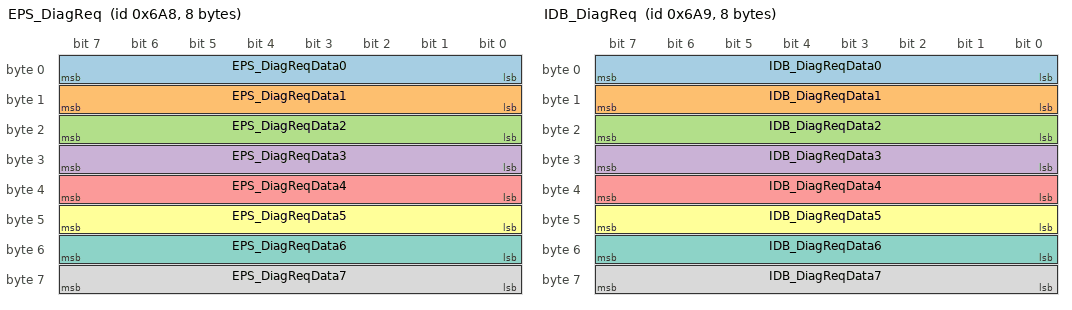
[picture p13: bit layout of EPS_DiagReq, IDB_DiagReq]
BO_ 1704 EPS_DiagReq: 8 XGW_Chassis
 SG_ EPS_DiagReqData0 : 7|8@0+ (1,0) [0|255] "-"  EPS
 SG_ EPS_DiagReqData1 : 15|8@0+ (1,0) [0|255] ""  EPS
 SG_ EPS_DiagReqData2 : 23|8@0+ (1,0) [0|255] ""  EPS
 SG_ EPS_DiagReqData3 : 31|8@0+ (1,0) [0|255] ""  EPS
 SG_ EPS_DiagReqData4 : 39|8@0+ (1,0) [0|255] "-"  EPS
 SG_ EPS_DiagReqData5 : 47|8@0+ (1,0) [0|255] "-"  EPS
 SG_ EPS_DiagReqData6 : 55|8@0+ (1,0) [0|255] "-"  EPS
 SG_ EPS_DiagReqData7 : 63|8@0+ (1,0) [0|255] ""  EPS

BO_ 1705 IDB_DiagReq: 8 XGW_Chassis
 SG_ IDB_DiagReqData0 : 7|8@0+ (1,0) [0|255] ""  IDB_Chassis
 SG_ IDB_DiagReqData1 : 15|8@0+ (1,0) [0|255] ""  IDB_Chassis
 SG_ IDB_DiagReqData2 : 23|8@0+ (1,0) [0|255] ""  IDB_Chassis
 SG_ IDB_DiagReqData3 : 31|8@0+ (1,0) [0|255] ""  IDB_Chassis
 SG_ IDB_DiagReqData4 : 39|8@0+ (1,0) [0|255] ""  IDB_Chassis
 SG_ IDB_DiagReqData5 : 47|8@0+ (1,0) [0|255] ""  IDB_Chassis
 SG_ IDB_DiagReqData6 : 55|8@0+ (1,0) [0|255] "-"  IDB_Chassis
 SG_ IDB_DiagReqData7 : 63|8@0+ (1,0) [0|255] ""  IDB_Chassis

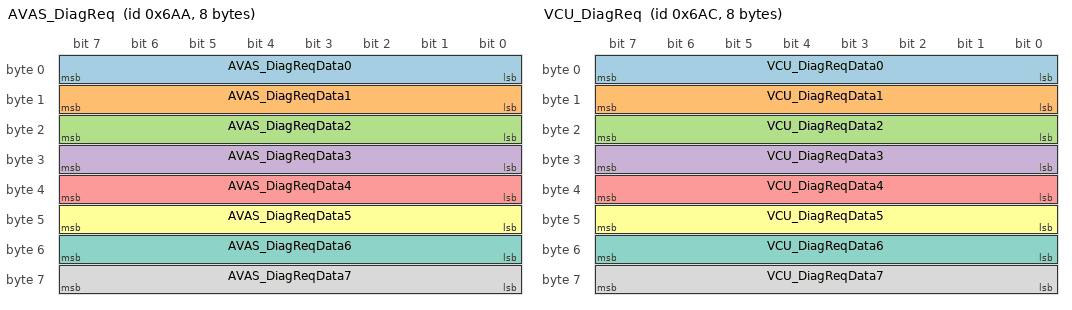
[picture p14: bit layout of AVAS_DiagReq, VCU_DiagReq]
BO_ 1706 AVAS_DiagReq: 8 XGW_Chassis
 SG_ AVAS_DiagReqData0 : 7|8@0+ (1,0) [0|255] "-"  AVAS
 SG_ AVAS_DiagReqData1 : 15|8@0+ (1,0) [0|255] ""  AVAS
 SG_ AVAS_DiagReqData2 : 23|8@0+ (1,0) [0|255] ""  AVAS
 SG_ AVAS_DiagReqData3 : 31|8@0+ (1,0) [0|255] "-"  AVAS
 SG_ AVAS_DiagReqData4 : 39|8@0+ (1,0) [0|255] ""  AVAS
 SG_ AVAS_DiagReqData5 : 47|8@0+ (1,0) [0|255] ""  AVAS
 SG_ AVAS_DiagReqData6 : 55|8@0+ (1,0) [0|255] ""  AVAS
 SG_ AVAS_DiagReqData7 : 63|8@0+ (1,0) [0|255] ""  AVAS

BO_ 1708 VCU_DiagReq: 8 XGW_Chassis
 SG_ VCU_DiagReqData0 : 7|8@0+ (1,0) [0|255] "-"  VCU_Chassis
 SG_ VCU_DiagReqData1 : 15|8@0+ (1,0) [0|255] ""  VCU_Chassis
 SG_ VCU_DiagReqData2 : 23|8@0+ (1,0) [0|255] "-"  VCU_Chassis
 SG_ VCU_DiagReqData3 : 31|8@0+ (1,0) [0|255] ""  VCU_Chassis
 SG_ VCU_DiagReqData4 : 39|8@0+ (1,0) [0|255] ""  VCU_Chassis
 SG_ VCU_DiagReqData5 : 47|8@0+ (1,0) [0|255] "-"  VCU_Chassis
 SG_ VCU_DiagReqData6 : 55|8@0+ (1,0) [0|255] ""  VCU_Chassis
 SG_ VCU_DiagReqData7 : 63|8@0+ (1,0) [0|255] "-"  VCU_Chassis

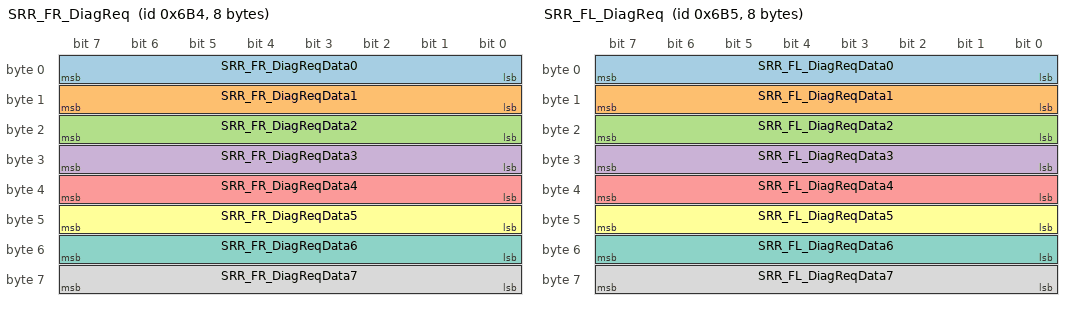
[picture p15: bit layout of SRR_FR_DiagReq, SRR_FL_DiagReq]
BO_ 1716 SRR_FR_DiagReq: 8 XGW_Chassis
 SG_ SRR_FR_DiagReqData0 : 7|8@0+ (1,0) [0|255] ""  ADAS_Chassis
 SG_ SRR_FR_DiagReqData1 : 15|8@0+ (1,0) [0|255] ""  ADAS_Chassis
 SG_ SRR_FR_DiagReqData2 : 23|8@0+ (1,0) [0|255] ""  ADAS_Chassis
 SG_ SRR_FR_DiagReqData3 : 31|8@0+ (1,0) [0|255] ""  ADAS_Chassis
 SG_ SRR_FR_DiagReqData4 : 39|8@0+ (1,0) [0|255] ""  ADAS_Chassis
 SG_ SRR_FR_DiagReqData5 : 47|8@0+ (1,0) [0|255] ""  ADAS_Chassis
 SG_ SRR_FR_DiagReqData6 : 55|8@0+ (1,0) [0|255] ""  ADAS_Chassis
 SG_ SRR_FR_DiagReqData7 : 63|8@0+ (1,0) [0|255] ""  ADAS_Chassis

BO_ 1717 SRR_FL_DiagReq: 8 XGW_Chassis
 SG_ SRR_FL_DiagReqData0 : 7|8@0+ (1,0) [0|255] ""  ADAS_Chassis
 SG_ SRR_FL_DiagReqData1 : 15|8@0+ (1,0) [0|255] ""  ADAS_Chassis
 SG_ SRR_FL_DiagReqData2 : 23|8@0+ (1,0) [0|255] ""  ADAS_Chassis
 SG_ SRR_FL_DiagReqData3 : 31|8@0+ (1,0) [0|255] ""  ADAS_Chassis
 SG_ SRR_FL_DiagReqData4 : 39|8@0+ (1,0) [0|255] ""  ADAS_Chassis
 SG_ SRR_FL_DiagReqData5 : 47|8@0+ (1,0) [0|255] ""  ADAS_Chassis
 SG_ SRR_FL_DiagReqData6 : 55|8@0+ (1,0) [0|255] ""  ADAS_Chassis
 SG_ SRR_FL_DiagReqData7 : 63|8@0+ (1,0) [0|255] ""  ADAS_Chassis

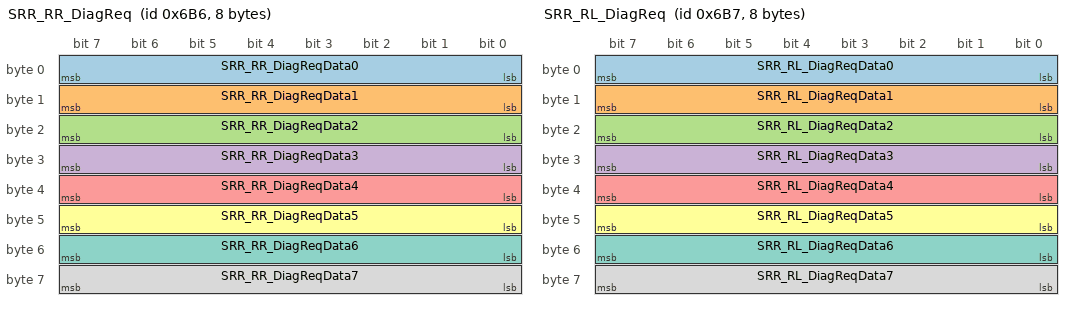
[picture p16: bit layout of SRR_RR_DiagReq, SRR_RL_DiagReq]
BO_ 1718 SRR_RR_DiagReq: 8 XGW_Chassis
 SG_ SRR_RR_DiagReqData0 : 7|8@0+ (1,0) [0|255] ""  ADAS_Chassis
 SG_ SRR_RR_DiagReqData1 : 15|8@0+ (1,0) [0|255] ""  ADAS_Chassis
 SG_ SRR_RR_DiagReqData2 : 23|8@0+ (1,0) [0|255] ""  ADAS_Chassis
 SG_ SRR_RR_DiagReqData3 : 31|8@0+ (1,0) [0|255] ""  ADAS_Chassis
 SG_ SRR_RR_DiagReqData4 : 39|8@0+ (1,0) [0|255] ""  ADAS_Chassis
 SG_ SRR_RR_DiagReqData5 : 47|8@0+ (1,0) [0|255] ""  ADAS_Chassis
 SG_ SRR_RR_DiagReqData6 : 55|8@0+ (1,0) [0|255] ""  ADAS_Chassis
 SG_ SRR_RR_DiagReqData7 : 63|8@0+ (1,0) [0|255] ""  ADAS_Chassis

BO_ 1719 SRR_RL_DiagReq: 8 XGW_Chassis
 SG_ SRR_RL_DiagReqData0 : 7|8@0+ (1,0) [0|255] ""  ADAS_Chassis
 SG_ SRR_RL_DiagReqData1 : 15|8@0+ (1,0) [0|255] ""  ADAS_Chassis
 SG_ SRR_RL_DiagReqData2 : 23|8@0+ (1,0) [0|255] ""  ADAS_Chassis
 SG_ SRR_RL_DiagReqData3 : 31|8@0+ (1,0) [0|255] ""  ADAS_Chassis
 SG_ SRR_RL_DiagReqData4 : 39|8@0+ (1,0) [0|255] ""  ADAS_Chassis
 SG_ SRR_RL_DiagReqData5 : 47|8@0+ (1,0) [0|255] ""  ADAS_Chassis
 SG_ SRR_RL_DiagReqData6 : 55|8@0+ (1,0) [0|255] ""  ADAS_Chassis
 SG_ SRR_RL_DiagReqData7 : 63|8@0+ (1,0) [0|255] ""  ADAS_Chassis

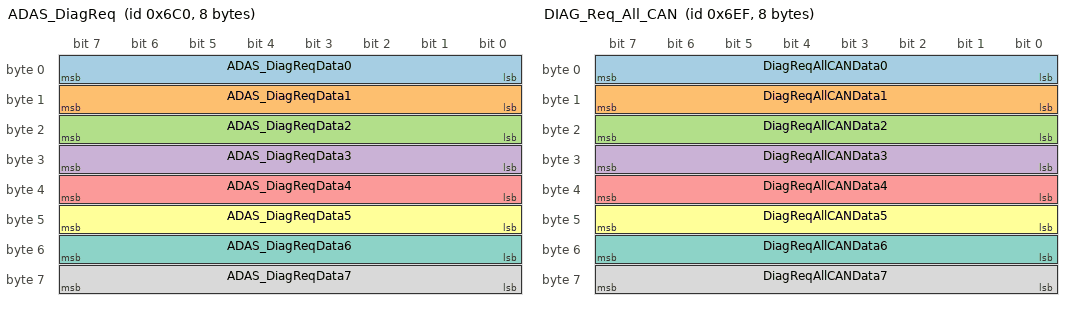
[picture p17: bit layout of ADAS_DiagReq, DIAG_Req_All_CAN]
BO_ 1728 ADAS_DiagReq: 8 XGW_Chassis
 SG_ ADAS_DiagReqData0 : 7|8@0+ (1,0) [0|255] ""  ADAS_Chassis,SCAM
 SG_ ADAS_DiagReqData1 : 15|8@0+ (1,0) [0|255] ""  ADAS_Chassis,SCAM
 SG_ ADAS_DiagReqData2 : 23|8@0+ (1,0) [0|255] ""  ADAS_Chassis,SCAM
 SG_ ADAS_DiagReqData3 : 31|8@0+ (1,0) [0|255] ""  ADAS_Chassis,SCAM
 SG_ ADAS_DiagReqData4 : 39|8@0+ (1,0) [0|255] ""  ADAS_Chassis,SCAM
 SG_ ADAS_DiagReqData5 : 47|8@0+ (1,0) [0|255] ""  ADAS_Chassis,SCAM
 SG_ ADAS_DiagReqData6 : 55|8@0+ (1,0) [0|255] ""  ADAS_Chassis,SCAM
 SG_ ADAS_DiagReqData7 : 63|8@0+ (1,0) [0|255] ""  ADAS_Chassis,SCAM

BO_ 1775 DIAG_Req_All_CAN: 8 XGW_Chassis
 SG_ DiagReqAllCANData0 : 7|8@0+ (1,0) [0|255] "-"  ADAS_Chassis,EPS,MRGEN,SCAM,SRR
 SG_ DiagReqAllCANData1 : 15|8@0+ (1,0) [0|255] ""  ADAS_Chassis,EPS,MRGEN,SCAM,SRR
 SG_ DiagReqAllCANData2 : 23|8@0+ (1,0) [0|255] "-"  ADAS_Chassis,EPS,MRGEN,SCAM,SRR
 SG_ DiagReqAllCANData3 : 31|8@0+ (1,0) [0|255] "-"  ADAS_Chassis,EPS,MRGEN,SCAM,SRR
 SG_ DiagReqAllCANData4 : 39|8@0+ (1,0) [0|255] ""  ADAS_Chassis,EPS,MRGEN,SCAM,SRR
 SG_ DiagReqAllCANData5 : 47|8@0+ (1,0) [0|255] ""  ADAS_Chassis,EPS,MRGEN,SCAM,SRR
 SG_ DiagReqAllCANData6 : 55|8@0+ (1,0) [0|255] ""  ADAS_Chassis,EPS,MRGEN,SCAM,SRR
 SG_ DiagReqAllCANData7 : 63|8@0+ (1,0) [0|255] ""  ADAS_Chassis,EPS,MRGEN,SCAM,SRR

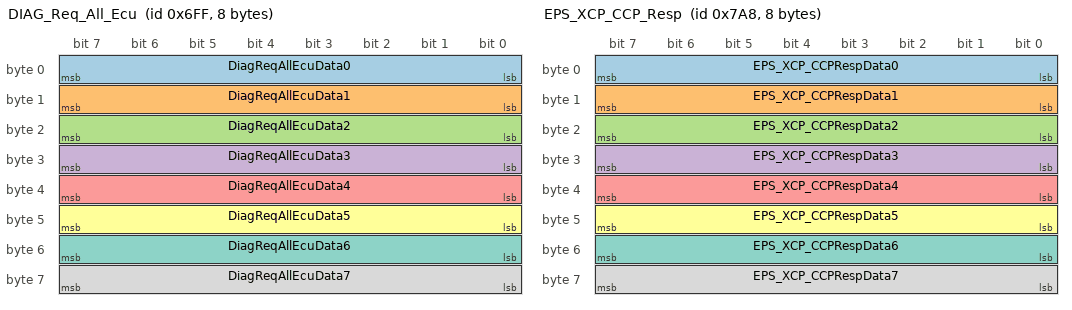
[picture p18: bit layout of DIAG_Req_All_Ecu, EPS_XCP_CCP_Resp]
BO_ 1791 DIAG_Req_All_Ecu: 8 XGW_Chassis
 SG_ DiagReqAllEcuData0 : 7|8@0+ (1,0) [0|255] "-"  ADAS_Chassis,EPS,MRGEN,SCAM,SRR
 SG_ DiagReqAllEcuData1 : 15|8@0+ (1,0) [0|255] ""  ADAS_Chassis,EPS,MRGEN,SCAM,SRR
 SG_ DiagReqAllEcuData2 : 23|8@0+ (1,0) [0|255] ""  ADAS_Chassis,EPS,MRGEN,SCAM,SRR
 SG_ DiagReqAllEcuData3 : 31|8@0+ (1,0) [0|255] ""  ADAS_Chassis,EPS,MRGEN,SCAM,SRR
 SG_ DiagReqAllEcuData4 : 39|8@0+ (1,0) [0|255] "-"  ADAS_Chassis,EPS,MRGEN,SCAM,SRR
 SG_ DiagReqAllEcuData5 : 47|8@0+ (1,0) [0|255] ""  ADAS_Chassis,EPS,MRGEN,SCAM,SRR
 SG_ DiagReqAllEcuData6 : 55|8@0+ (1,0) [0|255] ""  ADAS_Chassis,EPS,MRGEN,SCAM,SRR
 SG_ DiagReqAllEcuData7 : 63|8@0+ (1,0) [0|255] ""  ADAS_Chassis,EPS,MRGEN,SCAM,SRR

BO_ 1817 SEED_CAN_Req11_IDB_Chassis: 8 IDB_Chassis
 SG_ SEED_CAN_Req11 : 7|64@0+ (1,0) [0|1.84467440737096E+019] ""  SCAM,VCU_Chassis

BO_ 1827 SEED_CAN_Req13_VCU_Chassis: 8 VCU_Chassis
 SG_ SEED_CAN_Req13 : 7|64@0+ (1,0) [0|1.84467440737096E+019] ""  EPS,IDB_Chassis

BO_ 1829 SEED_CAN_Req14_EPS: 8 EPS
 SG_ SEED_CAN_Req14 : 7|64@0+ (1,0) [0|1.84467440737096E+019] ""  SCAM,VCU_Chassis

BO_ 1831 SEED_CAN_Req15_SCAM: 8 SCAM
 SG_ SEED_CAN_Req15 : 7|64@0+ (1,0) [0|1.84467440737096E+019] ""  EPS,IDB_Chassis

BO_ 1960 EPS_XCP_CCP_Resp: 8 EPS
 SG_ EPS_XCP_CCPRespData0 : 7|8@0+ (1,0) [0|255] ""  DUMMY_ECU
 SG_ EPS_XCP_CCPRespData1 : 15|8@0+ (1,0) [0|255] ""  DUMMY_ECU
 SG_ EPS_XCP_CCPRespData2 : 23|8@0+ (1,0) [0|255] ""  DUMMY_ECU
 SG_ EPS_XCP_CCPRespData3 : 31|8@0+ (1,0) [0|255] ""  DUMMY_ECU
 SG_ EPS_XCP_CCPRespData4 : 39|8@0+ (1,0) [0|255] ""  DUMMY_ECU
 SG_ EPS_XCP_CCPRespData5 : 47|8@0+ (1,0) [0|255] ""  DUMMY_ECU
 SG_ EPS_XCP_CCPRespData6 : 55|8@0+ (1,0) [0|255] ""  DUMMY_ECU
 SG_ EPS_XCP_CCPRespData7 : 63|8@0+ (1,0) [0|255] ""  DUMMY_ECU

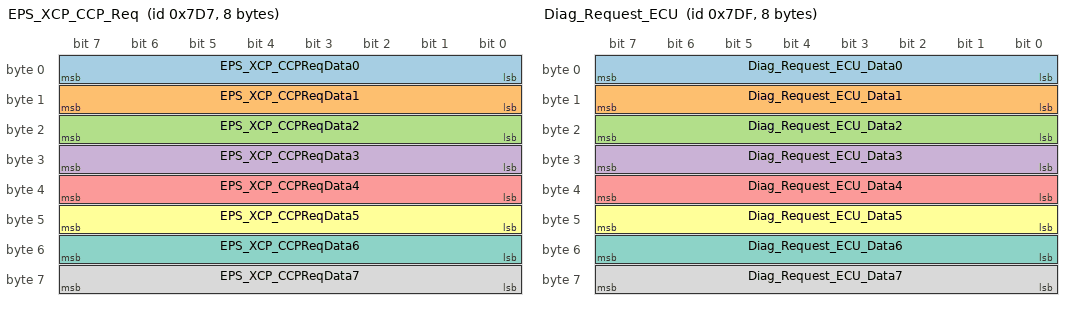
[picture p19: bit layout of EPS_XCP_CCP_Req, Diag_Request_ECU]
BO_ 2007 EPS_XCP_CCP_Req: 8 DUMMY_ECU
 SG_ EPS_XCP_CCPReqData0 : 7|8@0+ (1,0) [0|255] ""  EPS
 SG_ EPS_XCP_CCPReqData1 : 15|8@0+ (1,0) [0|255] ""  EPS
 SG_ EPS_XCP_CCPReqData2 : 23|8@0+ (1,0) [0|255] ""  EPS
 SG_ EPS_XCP_CCPReqData3 : 31|8@0+ (1,0) [0|255] ""  EPS
 SG_ EPS_XCP_CCPReqData4 : 39|8@0+ (1,0) [0|255] ""  EPS
 SG_ EPS_XCP_CCPReqData5 : 47|8@0+ (1,0) [0|255] ""  EPS
 SG_ EPS_XCP_CCPReqData6 : 55|8@0+ (1,0) [0|255] ""  EPS
 SG_ EPS_XCP_CCPReqData7 : 63|8@0+ (1,0) [0|255] ""  EPS

BO_ 2015 Diag_Request_ECU: 8 XGW_Chassis
 SG_ Diag_Request_ECU_Data0 : 7|8@0+ (1,0) [0|255] ""  ADAS_Chassis,AVAS,EPS,IDB_Chassis,MRGEN,RCU_Chassis,SCAM,SRR,VCU_Chassis,YSS
 SG_ Diag_Request_ECU_Data1 : 15|8@0+ (1,0) [0|255] "-"  ADAS_Chassis,AVAS,EPS,IDB_Chassis,MRGEN,RCU_Chassis,SCAM,SRR,VCU_Chassis,YSS
 SG_ Diag_Request_ECU_Data2 : 23|8@0+ (1,0) [0|255] "-"  ADAS_Chassis,AVAS,EPS,IDB_Chassis,MRGEN,RCU_Chassis,SCAM,SRR,VCU_Chassis,YSS
 SG_ Diag_Request_ECU_Data3 : 31|8@0+ (1,0) [0|255] ""  ADAS_Chassis,AVAS,EPS,IDB_Chassis,MRGEN,RCU_Chassis,SCAM,SRR,VCU_Chassis,YSS
 SG_ Diag_Request_ECU_Data4 : 39|8@0+ (1,0) [0|255] "-"  ADAS_Chassis,AVAS,EPS,IDB_Chassis,MRGEN,RCU_Chassis,SCAM,SRR,VCU_Chassis,YSS
 SG_ Diag_Request_ECU_Data5 : 47|8@0+ (1,0) [0|255] ""  ADAS_Chassis,AVAS,EPS,IDB_Chassis,MRGEN,RCU_Chassis,SCAM,SRR,VCU_Chassis,YSS
 SG_ Diag_Request_ECU_Data6 : 55|8@0+ (1,0) [0|255] "-"  ADAS_Chassis,AVAS,EPS,IDB_Chassis,MRGEN,RCU_Chassis,SCAM,SRR,VCU_Chassis,YSS
 SG_ Diag_Request_ECU_Data7 : 63|8@0+ (1,0) [0|255] ""  ADAS_Chassis,AVAS,EPS,IDB_Chassis,MRGEN,RCU_Chassis,SCAM,SRR,VCU_Chassis,YSS

CM_ BO_ 1039 "YSS_WarnMsg";
CM_ SG_ 1039 CHSKM_YSS_WarnMsg "Checksum";
CM_ SG_ 1039 ALV_YSS_WarnMsg "Alive Counter";
CM_ SG_ 1039 YSS_Warning_Flag_1 "Warning Message Flag, Component owner, Supplier align and define for this signal";
CM_ SG_ 1039 YSS_Warning_Flag_2 "Warning Message Flag, Component owner, Supplier align and define for this signal";
CM_ SG_ 1039 YSS_Warning_Flag_3 "Warning Message Flag, Component owner, Supplier align and define for this signal";
CM_ SG_ 1039 YSS_Warning_Flag_4 "Warning Message Flag, Component owner, Supplier align and define for this signal";
CM_ SG_ 1039 YSS_Warning_Flag_5 "Warning Message Flag, Component owner, Supplier align and define for this signal";
CM_ SG_ 1039 YSS_Warning_Flag_6 "Warning Message Flag, Component owner, Supplier align and define for this signal";
CM_ SG_ 1039 YSS_Warning_Flag_7 "Warning Message Flag, Component owner, Supplier align and define for this signal";
CM_ SG_ 1039 YSS_Warning_Flag_8 "Warning Message Flag, Component owner, Supplier align and define for this signal";
CM_ SG_ 1039 YSS_Warning_Flag_9 "Warning Message Flag, Component owner, Supplier align and define for this signal";
CM_ SG_ 1039 YSS_Warning_Flag_10 "Warning Message Flag, Component owner, Supplier align and define for this signal";
CM_ SG_ 1039 YSS_Warning_Flag_11 "Warning Message Flag, Component owner, Supplier align and define for this signal";
CM_ SG_ 1039 YSS_Warning_Flag_12 "Warning Message Flag, Component owner, Supplier align and define for this signal";
CM_ SG_ 1039 YSS_Reserved_signal1 "Warning Message Flag, Component owner, Supplier align and define for this signal";
CM_ SG_ 1039 YSS_Reserved_signal2 "Warning Message Flag, Component owner, Supplier align and define for this signal";
CM_ SG_ 1039 YSS_Reserved_signal3 "Warning Message Flag, Component owner, Supplier align and define for this signal";
CM_ SG_ 1039 YSS_Reserved_signal4 "Warning Message Flag, Component owner, Supplier align and define for this signal";
CM_ SG_ 1039 YSS_Reserved_signal5 "Warning Message Flag, Component owner, Supplier align and define for this signal";
CM_ BO_ 1059 "AVAS STATUS";
CM_ SG_ 1059 AVAS_BatteryUnderVoltage "Battery voltage below threshold
";
CM_ SG_ 1059 AVAS_BatteryOverVoltage "Battery voltage over threshold
";
CM_ SG_ 1059 AVAS_VINInfoNotPrgm "VIN code is not saved";
CM_ SG_ 1059 AVAS_AMPVoltSplDrvOperationFail "AMP voltage supply drive operation fail
";
CM_ SG_ 1059 AVAS_AMPIntFaultOverCurr "Amplifier internal overcurrent fail";
CM_ SG_ 1059 AVAS_AMPInternalFaultDCError "Amplifier internal DC fault";
CM_ SG_ 1059 AVAS_AMPInternalFaultOverTemp "Amplifier internal over-temperature fault";
CM_ SG_ 1059 AVAS_AMPInternalFaultClockError "Amplifier internal clock fault
";
CM_ SG_ 1059 AVAS_SpkrMntPwrSwDrvHighFlt "Speaker monitor power switch drive high fault
";
CM_ SG_ 1059 AVAS_SpkrMntPwrSwDrvLowFlt "speaker power switch drive low fault
";
CM_ SG_ 1059 AVAS_InternalSpeakerOpen "Internal speaker open";
CM_ SG_ 1059 AVAS_ECUMalFlshOperationErr "ECU malfunction : flash operation error";
CM_ SG_ 1059 AVAS_ECUMalfunctionRamFailure "ECU malfunction : RAM failure
";
CM_ SG_ 1059 AVAS_ECUMalEEPROMFailure "EEPROM operation fail";
CM_ SG_ 1059 AVAS_CANBusOff "CAN Bus off
";
CM_ SG_ 1059 AVAS_LossCommVehicleSpeed "Loss Communication with vehicle speed signal";
CM_ SG_ 1059 AVAS_LossCommGearPosition "Loss Communication with gear position signal";
CM_ SG_ 1059 AVAS_LossCommAVASCloseCmd "Loss Communication with avas close command signal";
CM_ BO_ 1060 "AVAS SHMNumber";
CM_ SG_ 1060 AVAS_SWNumber "SoftWare Number";
CM_ SG_ 1060 AVAS_HWNumber "HardWare Number";
CM_ SG_ 1060 AVAS_MXNumber "Matrix Number";
CM_ BO_ 1061 "VCU AVAS GearPosition ECU";
CM_ SG_ 1061 ActualGearShiftPosition "VCU_ActualGearShiftPosition";
CM_ BO_ 1062 "VCU AVAS VehicleSpeed ECU";
CM_ SG_ 1062 ESP_VehicleSpeed "Vehicle speed out";
CM_ SG_ 1062 VCU_STAT_Terminal_BEV "Represent the status of physical terminal";
CM_ BO_ 1063 "VCU AVAS Close Cmd";
CM_ SG_ 1063 IPC_AVASCloseCmd "AVAS Close Cmd";
CM_ BO_ 1064 "TRM fitted status and keyfob left the car warning";
CM_ SG_ 1064 BCM_Keyfob_Leftcar "Keyfob left the car warning";
CM_ SG_ 1064 TRMFitted "Signal indicating that TRM is fitted or not. Signal is copy of H16 parameter in the VOD setting withing XGW";
CM_ BO_ 1072 "ADAS_DMS";
CM_ SG_ 1072 ADAS_DMS_Checksum "Checksum";
CM_ SG_ 1072 ADAS_DMS_Alive "Alive Counter";
CM_ SG_ 1072 ADAS_DMS_HapWarning "ADAS_DMS_HapWarning";
CM_ BO_ 1074 "MHU_FOTA_STATUS";
CM_ SG_ 1074 MHU_FOTA_Checksum "FOTA global status message checksum";
CM_ SG_ 1074 MHU_FOTA_Alive_Counter "FOTA global status message alive counter";
CM_ SG_ 1074 MHU_FOTA_State "FOTA global status";
CM_ SG_ 1074 MHU_FOTA_Error_Code "FOTA Error Code";
CM_ BO_ 1095 "MHU_CarMode_Switch";
CM_ SG_ 1095 CHKSM_MHU_SET_CarMode "Checksum";
CM_ SG_ 1095 ALV_MHU_SET_CarMode "Alive counter";
CM_ SG_ 1095 MHU_Request_CarOFF "MHU request Car go to OFF state";
CM_ SG_ 1095 MHU_SET_ChildMode "Set Car in Child mode which keep climate control running and delay CPD (EU NCAP requirement)";
CM_ SG_ 1095 MHU_SET_GameMode "Set Car in Game mode";
CM_ SG_ 1095 MHU_SET_KaraokeMode "Set Car in Karaoket mode";
CM_ SG_ 1095 MHU_SET_WashMode "Set Car in Wash mode";
CM_ SG_ 1095 MHU_SET_StopMode "Set Car Stop mode";
CM_ BO_ 1191 "RCU warning message";
CM_ SG_ 1191 CHSKM_RCU_WarnMsg "Checksum";
CM_ SG_ 1191 ALV_RCU_WarnMsg "Alive Counter";
CM_ SG_ 1191 RCU_DAA_NoOpDoorOpen "EPB DAA can not be operated due to Driver Door open";
CM_ SG_ 1191 RCU_EHandBrk_fault "Electric park brake malfunction, HU mode, Maintenance mode, Bulb check";
CM_ SG_ 1191 RCU_EOL_NotDone "EOL configuration is not completely done";
CM_ SG_ 1191 RCU_ECD_RWU_active "ECD/RWU active";
CM_ SG_ 1191 RCU_ParkOnSteepInclination "Vehicle park on a steep inclination";
CM_ SG_ 1191 RCU_BrkForceNotEnough "Brake force not enough, Demand clamp force not achieved";
CM_ SG_ 1191 RCU_ReleaseEPB_Wo_PressBrk "Driver Try to release EPB without press brake pedal";
CM_ SG_ 1191 RCU_ParkBrkApplied "Parking Brake applied";
CM_ SG_ 1191 RCU_Swch_Mafnc "EPB switch is malfunction or brakes are incoherent";
CM_ SG_ 1191 RCU_DAA_NoOpBeltUnbuckled "EPB DAA can not be operated due to Driver unbuckled";
CM_ SG_ 1191 RCU_RollerBenchMode "Roller Bench mode of RCU";
CM_ SG_ 1191 RCU_EPB_ParkLampState "Electric Parking Brake Lamp request";
CM_ SG_ 1191 RCU_EPB_WarnLampState "EPB Warning Lamp request";
CM_ SG_ 1191 RCU_WflagRes36 "Reserved VCU Warning message";
CM_ SG_ 1191 RCU_WflagRes37 "Reserved VCU Warning message";
CM_ SG_ 1191 RCU_WflagRes38 "Reserved VCU Warning message";
CM_ SG_ 1191 RCU_WflagRes39 "Reserved VCU Warning message";
CM_ SG_ 1191 RCU_WflagRes40 "Reserved VCU Warning message";
CM_ SG_ 1191 RCU_WflagRes41 "Reserved VCU Warning message";
CM_ SG_ 1191 RCU_WflagRes42 "Reserved VCU Warning message";
CM_ SG_ 1191 RCU_WflagRes43 "Reserved VCU Warning message";
CM_ SG_ 1191 RCU_WflagRes44 "Reserved VCU Warning message";
CM_ SG_ 1191 RCU_WflagRes45 "Reserved VCU Warning message";
CM_ SG_ 1191 RCU_WflagRes46 "Reserved VCU Warning message";
CM_ SG_ 1191 RCU_WflagRes47 "Reserved VCU Warning message";
CM_ SG_ 1191 RCU_Reserved_signal1 "Warning Message Flag, Component owner, Supplier align and define for this signal";
CM_ BO_ 1192 "EPS warning message";
CM_ SG_ 1192 CHSKM_EPS_WarnMsg "Checksum";
CM_ SG_ 1192 ALV_EPS_WarnMsg "Alive Counter";
CM_ SG_ 1192 EPS_Malfunction "EPS malfunction, No Power Assistance Steering Available";
CM_ SG_ 1192 EPS_Reduced "EPS reduced, Power Steering Assistance Reduced";
CM_ SG_ 1192 EPS_Overheat " EPS Overheat, No Power Assistance Steering Available";
CM_ SG_ 1192 EPS_NotReady "EPS is not ready, No Power Assistance Steering Available";
CM_ SG_ 1192 EPS_Warning_Flag_5 "Warning Message Flag, Component owner, Supplier align and define for this signal";
CM_ SG_ 1192 EPS_Warning_Flag_6 "Warning Message Flag, Component owner, Supplier align and define for this signal";
CM_ SG_ 1192 EPS_Warning_Flag_7 "Warning Message Flag, Component owner, Supplier align and define for this signal";
CM_ SG_ 1192 EPS_Warning_Flag_8 "Warning Message Flag, Component owner, Supplier align and define for this signal";
CM_ SG_ 1192 EPS_Warning_Flag_9 "Warning Message Flag, Component owner, Supplier align and define for this signal";
CM_ SG_ 1192 EPS_Warning_Flag_10 "Warning Message Flag, Component owner, Supplier align and define for this signal";
CM_ SG_ 1192 EPS_Warning_Flag_11 "Warning Message Flag, Component owner, Supplier align and define for this signal";
CM_ SG_ 1192 EPS_Warning_Flag_12 "Warning Message Flag, Component owner, Supplier align and define for this signal";
CM_ SG_ 1192 EPS_Reserved_signal1 "Warning Message Flag, Component owner, Supplier align and define for this signal";
CM_ SG_ 1192 EPS_Reserved_signal2 "Warning Message Flag, Component owner, Supplier align and define for this signal";
CM_ SG_ 1192 EPS_Reserved_signal3 "Warning Message Flag, Component owner, Supplier align and define for this signal";
CM_ SG_ 1192 EPS_Reserved_signal4 "Warning Message Flag, Component owner, Supplier align and define for this signal";
CM_ SG_ 1192 EPS_Reserved_signal5 "Warning Message Flag, Component owner, Supplier align and define for this signal";
CM_ BO_ 1193 "IDB warning message";
CM_ SG_ 1193 CHSKM_IDB_WarnMsg "Checksum";
CM_ SG_ 1193 ALV_IDB_WarnMsg "Alive Counter";
CM_ SG_ 1193 IDB_ESC_fault "IDB Malfunction warning";
CM_ SG_ 1193 IDB_ABS_fault "Anti-lock Braking System fault warning";
CM_ SG_ 1193 IDB_BrkLowFluid "Brake Fluid low warning";
CM_ SG_ 1193 IDB_BrkSysFault "Brake system fault warning";
CM_ SG_ 1193 IDB_fault "IDB Malfunction warning";
CM_ SG_ 1193 IDB_HydraulicBrkAssist_Fault "HBA malfunction warning, Hydraulic brake assist ";
CM_ SG_ 1193 IDB_HAS_Fault "Hill start assist malfunction warning";
CM_ SG_ 1193 IDB_TSM_Fault "Trailer Sway mitigation malfunction warning";
CM_ SG_ 1193 IDB_Reserved_signal2 "Warning Message Flag, Component owner, Supplier align and define for this signal";
CM_ SG_ 1193 IDB_Reserved_signal3 "Warning Message Flag, Component owner, Supplier align and define for this signal";
CM_ SG_ 1193 IDB_Reserved_signal4 "Warning Message Flag, Component owner, Supplier align and define for this signal";
CM_ SG_ 1193 IDB_Reserved_signal5 "Warning Message Flag, Component owner, Supplier align and define for this signal";
CM_ BO_ 1282 "XGW Network Management";
CM_ SG_ 1282 XGW_srcNodeID "Network Management Signal";
CM_ SG_ 1282 XGW_CtrlBitVector "Network Management Signal";
CM_ SG_ 1282 XGW_usrData0 "Network Management Signal";
CM_ SG_ 1282 XGW_usrData1 "Network Management Signal";
CM_ SG_ 1282 XGW_usrData2 "Network Management Signal";
CM_ SG_ 1282 XGW_usrData3 "Network Management Signal";
CM_ SG_ 1282 XGW_usrData4 "Network Management Signal";
CM_ SG_ 1282 XGW_usrData5 "Network Management Signal";
CM_ BO_ 1317 "RCU Network Management";
CM_ SG_ 1317 RCU_srcNodeID "Network Management Signal";
CM_ SG_ 1317 RCU_usrData0 "Network Management Signal";
CM_ SG_ 1317 RCU_usrData1 "Network Management Signal";
CM_ SG_ 1317 RCU_usrData2 "Network Management Signal";
CM_ SG_ 1317 RCU_usrData3 "Network Management Signal";
CM_ SG_ 1317 RCU_usrData4 "Network Management Signal";
CM_ SG_ 1317 RCU_usrData5 "Network Management Signal";
CM_ BO_ 1321 "IDB Network Management";
CM_ SG_ 1321 IDB_srcNodeID "Network Management Signal";
CM_ SG_ 1321 IDB_CtrlBitVector "Network Management Signal";
CM_ SG_ 1321 IDB_usrData0 "Network Management Signal";
CM_ SG_ 1321 IDB_usrData1 "Network Management Signal";
CM_ SG_ 1321 IDB_usrData2 "Network Management Signal";
CM_ SG_ 1321 IDB_usrData3 "Network Management Signal";
CM_ SG_ 1321 IDB_usrData4 "Network Management Signal";
CM_ SG_ 1321 IDB_usrData5 "Network Management Signal";
CM_ BO_ 1324 "VCU Network Management";
CM_ SG_ 1324 VCU_srcNodeID "Network Management Signal";
CM_ SG_ 1324 VCU_CtrlBitVector "Network Management Signal";
CM_ SG_ 1324 VCU_usrData0 "Network Management Signal";
CM_ SG_ 1324 VCU_usrData1 "Network Management Signal";
CM_ SG_ 1324 VCU_usrData2 "Network Management Signal";
CM_ SG_ 1324 VCU_usrData3 "Network Management Signal";
CM_ SG_ 1324 VCU_usrData4 "Network Management Signal";
CM_ SG_ 1324 VCU_usrData5 "Network Management Signal";
CM_ BO_ 1344 "ADAS NM";
CM_ SG_ 1344 ADAS_srcNodeID "Network Management Signal";
CM_ SG_ 1344 ADAS_CtrlBitVector "Network Management Signal";
CM_ SG_ 1344 ADAS_usrData0 "Network Management Signal";
CM_ SG_ 1344 ADAS_usrData1 "Network Management Signal";
CM_ SG_ 1344 ADAS_usrData2 "Network Management Signal";
CM_ SG_ 1344 ADAS_usrData3 "Network Management Signal";
CM_ SG_ 1344 ADAS_usrData4 "Network Management Signal";
CM_ SG_ 1344 ADAS_usrData5 "Network Management Signal";
CM_ BO_ 1551 "Diagnostic Response for YSS     ";
CM_ SG_ 1551 YSS_DiagRespData0 "Diagnostic signal Data response";
CM_ SG_ 1551 YSS_DiagRespData1 "Diagnostic signal Data response";
CM_ SG_ 1551 YSS_DiagRespData2 "Diagnostic signal Data response";
CM_ SG_ 1551 YSS_DiagRespData3 "Diagnostic signal Data response";
CM_ SG_ 1551 YSS_DiagRespData4 "Diagnostic signal Data response";
CM_ SG_ 1551 YSS_DiagRespData5 "Diagnostic signal Data response";
CM_ SG_ 1551 YSS_DiagRespData6 "Diagnostic signal Data response";
CM_ SG_ 1551 YSS_DiagRespData7 "Diagnostic signal Data response";
CM_ BO_ 1573 "MRGEN_DiagResp";
CM_ SG_ 1573 MRGEN_DiagRespData0 "Diagnostic signal Data response";
CM_ SG_ 1573 MRGEN_DiagRespData1 "Remote Diagnostic signal Data response
";
CM_ SG_ 1573 MRGEN_DiagRespData2 "Diagnostic signal Data response";
CM_ SG_ 1573 MRGEN_DiagRespData3 "Diagnostic signal Data response";
CM_ SG_ 1573 MRGEN_DiagRespData4 "Diagnostic signal Data response";
CM_ SG_ 1573 MRGEN_DiagRespData5 "Diagnostic signal Data response";
CM_ SG_ 1573 MRGEN_DiagRespData6 "Diagnostic signal Data response";
CM_ SG_ 1573 MRGEN_DiagRespData7 "Remote Diagnostic signal Data response
";
CM_ BO_ 1574 "SCAM_DiagReq";
CM_ SG_ 1574 SCAM_DiagRespData0 "Diagnostic signal Data response";
CM_ SG_ 1574 SCAM_DiagRespData1 "Diagnostic signal Data response";
CM_ SG_ 1574 SCAM_DiagRespData2 "Diagnostic signal Data response";
CM_ SG_ 1574 SCAM_DiagRespData3 "Diagnostic signal Data response";
CM_ SG_ 1574 SCAM_DiagRespData4 "Diagnostic signal Data response";
CM_ SG_ 1574 SCAM_DiagRespData5 "Remote Diagnostic signal Data response";
CM_ SG_ 1574 SCAM_DiagRespData6 "Diagnostic signal Data response";
CM_ SG_ 1574 SCAM_DiagRespData7 "Diagnostic signal Data response";
CM_ BO_ 1575 "Diagnostic Response for RCU     ";
CM_ SG_ 1575 RCU_DiagRespData0 "Diagnostic signal Data response";
CM_ SG_ 1575 RCU_DiagRespData1 "Diagnostic signal Data response";
CM_ SG_ 1575 RCU_DiagRespData2 "Diagnostic signal Data response";
CM_ SG_ 1575 RCU_DiagRespData3 "Diagnostic signal Data response";
CM_ SG_ 1575 RCU_DiagRespData4 "Diagnostic signal Data response";
CM_ SG_ 1575 RCU_DiagRespData5 "Diagnostic signal Data response...";
CM_ SG_ 1575 RCU_DiagRespData6 "Diagnostic signal Data response";
CM_ SG_ 1575 RCU_DiagRespData7 "Diagnostic signal Data response...";
CM_ BO_ 1576 "Diagnostic response";
CM_ SG_ 1576 EPS_DiagRespData0 "Remote Diagnostic signal Data response";
CM_ SG_ 1576 EPS_DiagRespData1 "Diagnostic signal Data response";
CM_ SG_ 1576 EPS_DiagRespData2 "Diagnostic signal Data response";
CM_ SG_ 1576 EPS_DiagRespData3 "Remote Diagnostic signal Data response";
CM_ SG_ 1576 EPS_DiagRespData4 "Diagnostic signal Data response";
CM_ SG_ 1576 EPS_DiagRespData5 "Diagnostic signal Data response";
CM_ SG_ 1576 EPS_DiagRespData6 "Remote Diagnostic signal Data response";
CM_ SG_ 1576 EPS_DiagRespData7 "Remote Diagnostic signal Data response";
CM_ BO_ 1577 "IDB Diagnostic Response";
CM_ SG_ 1577 IDB_DiagRespData0 "Diagnostic signal Data response";
CM_ SG_ 1577 IDB_DiagRespData1 "Remote Diagnostic signal Data response";
CM_ SG_ 1577 IDB_DiagRespData2 "Remote Diagnostic signal Data response";
CM_ SG_ 1577 IDB_DiagRespData3 "Diagnostic signal Data response";
CM_ SG_ 1577 IDB_DiagRespData4 "Diagnostic signal Data response";
CM_ SG_ 1577 IDB_DiagRespData5 "Remote Diagnostic signal Data response";
CM_ SG_ 1577 IDB_DiagRespData6 "Remote Diagnostic signal Data response";
CM_ SG_ 1577 IDB_DiagRespData7 "Diagnostic signal Data response";
CM_ BO_ 1578 "AVAS Diagnostic Responde";
CM_ SG_ 1578 AVAS_DiagRespData0 "Diagnostic signal Data response";
CM_ SG_ 1578 AVAS_DiagRespData1 "Diagnostic signal Data response";
CM_ SG_ 1578 AVAS_DiagRespData2 "Diagnostic signal Data response";
CM_ SG_ 1578 AVAS_DiagRespData3 "Diagnostic signal Data response";
CM_ SG_ 1578 AVAS_DiagRespData4 "Diagnostic signal Data response";
CM_ SG_ 1578 AVAS_DiagRespData5 "Diagnostic signal Data response";
CM_ SG_ 1578 AVAS_DiagRespData6 "Diagnostic signal Data response";
CM_ SG_ 1578 AVAS_DiagRespData7 "Remote Diagnostic signal Data response";
CM_ BO_ 1580 "VCU Diagnostic Responde";
CM_ SG_ 1580 VCU_DiagRespData0 "Diagnostic signal Data response";
CM_ SG_ 1580 VCU_DiagRespData1 "Diagnostic signal Data response";
CM_ SG_ 1580 VCU_DiagRespData2 "Diagnostic signal Data response";
CM_ SG_ 1580 VCU_DiagRespData3 "Diagnostic signal Data response";
CM_ SG_ 1580 VCU_DiagRespData4 "Remote Diagnostic signal Data response";
CM_ SG_ 1580 VCU_DiagRespData5 "Diagnostic signal Data response";
CM_ SG_ 1580 VCU_DiagRespData6 "Diagnostic signal Data response";
CM_ SG_ 1580 VCU_DiagRespData7 "Remote Diagnostic signal Data response";
CM_ BO_ 1588 "SRR FR Diagnostic Response";
CM_ SG_ 1588 SRR_FR_DiagRespData0 "SRR_Diagnostic Response";
CM_ SG_ 1588 SRR_FR_DiagRespData1 "SRR_Diagnostic Response";
CM_ SG_ 1588 SRR_FR_DiagRespData2 "SRR_Diagnostic Response";
CM_ SG_ 1588 SRR_FR_DiagRespData3 "SRR_Diagnostic Response";
CM_ SG_ 1588 SRR_FR_DiagRespData4 "SRR_Diagnostic Response";
CM_ SG_ 1588 SRR_FR_DiagRespData5 "SRR_Diagnostic Response";
CM_ SG_ 1588 SRR_FR_DiagRespData6 "SRR_Diagnostic Response";
CM_ SG_ 1588 SRR_FR_DiagRespData7 "SRR_Diagnostic Response";
CM_ BO_ 1589 "SRR FL Diagnostic Response";
CM_ SG_ 1589 SRR_FL_DiagRespData0 "SRR_Diagnostic Response";
CM_ SG_ 1589 SRR_FL_DiagRespData1 "SRR_Diagnostic Response";
CM_ SG_ 1589 SRR_FL_DiagRespData2 "SRR_Diagnostic Response";
CM_ SG_ 1589 SRR_FL_DiagRespData3 "SRR_Diagnostic Response";
CM_ SG_ 1589 SRR_FL_DiagRespData4 "SRR_Diagnostic Response";
CM_ SG_ 1589 SRR_FL_DiagRespData5 "SRR_Diagnostic Response";
CM_ SG_ 1589 SRR_FL_DiagRespData6 "SRR_Diagnostic Response";
CM_ SG_ 1589 SRR_FL_DiagRespData7 "SRR_Diagnostic Response";
CM_ BO_ 1590 "SRR RR Diagnostic Response";
CM_ SG_ 1590 SRR_RR_DiagRespData0 "SRR_Diagnostic Response";
CM_ SG_ 1590 SRR_RR_DiagRespData1 "SRR_Diagnostic Response";
CM_ SG_ 1590 SRR_RR_DiagRespData2 "SRR_Diagnostic Response";
CM_ SG_ 1590 SRR_RR_DiagRespData3 "SRR_Diagnostic Response";
CM_ SG_ 1590 SRR_RR_DiagRespData4 "SRR_Diagnostic Response";
CM_ SG_ 1590 SRR_RR_DiagRespData5 "SRR_Diagnostic Response";
CM_ SG_ 1590 SRR_RR_DiagRespData6 "SRR_Diagnostic Response";
CM_ SG_ 1590 SRR_RR_DiagRespData7 "SRR_Diagnostic Response";
CM_ BO_ 1591 "SRR RL Diagnostic Response";
CM_ SG_ 1591 SRR_RL_DiagRespData0 "SRR_Diagnostic Response";
CM_ SG_ 1591 SRR_RL_DiagRespData1 "SRR_Diagnostic Response";
CM_ SG_ 1591 SRR_RL_DiagRespData2 "SRR_Diagnostic Response";
CM_ SG_ 1591 SRR_RL_DiagRespData3 "SRR_Diagnostic Response";
CM_ SG_ 1591 SRR_RL_DiagRespData4 "SRR_Diagnostic Response";
CM_ SG_ 1591 SRR_RL_DiagRespData5 "SRR_Diagnostic Response";
CM_ SG_ 1591 SRR_RL_DiagRespData6 "SRR_Diagnostic Response";
CM_ SG_ 1591 SRR_RL_DiagRespData7 "SRR_Diagnostic Response";
CM_ BO_ 1600 "ADAS DiagResp";
CM_ SG_ 1600 ADAS_DiagRespData0 "Diagnostic signal Data response";
CM_ SG_ 1600 ADAS_DiagRespData1 "Diagnostic signal Data response";
CM_ SG_ 1600 ADAS_DiagRespData2 "Diagnostic signal Data response";
CM_ SG_ 1600 ADAS_DiagRespData3 "Diagnostic signal Data response";
CM_ SG_ 1600 ADAS_DiagRespData4 "Diagnostic signal Data response";
CM_ SG_ 1600 ADAS_DiagRespData5 "Diagnostic signal Data response";
CM_ SG_ 1600 ADAS_DiagRespData6 "Diagnostic signal Data response";
CM_ SG_ 1600 ADAS_DiagRespData7 "Diagnostic signal Data response";
CM_ BO_ 1679 "Diagnostic Request for YSS     ";
CM_ SG_ 1679 YSS_DiagReqData0 "Diagnostic signal Data request";
CM_ SG_ 1679 YSS_DiagReqData1 "Diagnostic signal Data request";
CM_ SG_ 1679 YSS_DiagReqData2 "Diagnostic signal Data request";
CM_ SG_ 1679 YSS_DiagReqData3 "Diagnostic signal Data request";
CM_ SG_ 1679 YSS_DiagReqData4 "Remote Diagnostic signal Data request";
CM_ SG_ 1679 YSS_DiagReqData5 "Diagnostic signal Data request";
CM_ SG_ 1679 YSS_DiagReqData6 "Diagnostic signal Data request";
CM_ SG_ 1679 YSS_DiagReqData7 "Diagnostic signal Data request";
CM_ BO_ 1701 "MRGEN_DiagReq";
CM_ SG_ 1701 MRGEN_DiagReqData0 "Diagnostic signal Data request";
CM_ SG_ 1701 MRGEN_DiagReqData1 "Diagnostic signal Data request";
CM_ SG_ 1701 MRGEN_DiagReqData2 "Diagnostic signal Data request";
CM_ SG_ 1701 MRGEN_DiagReqData3 "Diagnostic signal Data request";
CM_ SG_ 1701 MRGEN_DiagReqData4 "Diagnostic signal Data request";
CM_ SG_ 1701 MRGEN_DiagReqData5 "Remote Diagnostic signal Data request
";
CM_ SG_ 1701 MRGEN_DiagReqData6 "Diagnostic signal Data request";
CM_ SG_ 1701 MRGEN_DiagReqData7 "Diagnostic signal Data request";
CM_ BO_ 1702 "SCAM_DiagReq";
CM_ SG_ 1702 SCAM_DiagReqData0 "Remote Diagnostic signal Data request";
CM_ SG_ 1702 SCAM_DiagReqData1 "Diagnostic signal Data request";
CM_ SG_ 1702 SCAM_DiagReqData2 "Remote Diagnostic signal Data request";
CM_ SG_ 1702 SCAM_DiagReqData3 "Remote Diagnostic signal Data request";
CM_ SG_ 1702 SCAM_DiagReqData4 "Diagnostic signal Data request";
CM_ SG_ 1702 SCAM_DiagReqData5 "Remote Diagnostic signal Data request";
CM_ SG_ 1702 SCAM_DiagReqData6 "Remote Diagnostic signal Data request";
CM_ SG_ 1702 SCAM_DiagReqData7 "Remote Diagnostic signal Data request";
CM_ BO_ 1703 "Diagnostic Request for RCU     ";
CM_ SG_ 1703 RCU_DiagReqData0 "Diagnostic signal Data request";
CM_ SG_ 1703 RCU_DiagReqData1 "Diagnostic signal Data request";
CM_ SG_ 1703 RCU_DiagReqData2 "Diagnostic signal Data request";
CM_ SG_ 1703 RCU_DiagReqData3 "Diagnostic signal Data request";
CM_ SG_ 1703 RCU_DiagReqData4 "Remote Diagnostic signal Data request";
CM_ SG_ 1703 RCU_DiagReqData5 "Diagnostic signal Data request";
CM_ SG_ 1703 RCU_DiagReqData6 "Remote Diagnostic signal Data request";
CM_ SG_ 1703 RCU_DiagReqData7 "Remote Diagnostic signal Data request";
CM_ BO_ 1704 "Diagnostic request";
CM_ SG_ 1704 EPS_DiagReqData0 "Remote Diagnostic signal Data request";
CM_ SG_ 1704 EPS_DiagReqData1 "Diagnostic signal Data request";
CM_ SG_ 1704 EPS_DiagReqData2 "Diagnostic signal Data request";
CM_ SG_ 1704 EPS_DiagReqData3 "Diagnostic signal Data request";
CM_ SG_ 1704 EPS_DiagReqData4 "Remote Diagnostic signal Data request";
CM_ SG_ 1704 EPS_DiagReqData5 "Remote Diagnostic signal Data request";
CM_ SG_ 1704 EPS_DiagReqData6 "Remote Diagnostic signal Data request";
CM_ SG_ 1704 EPS_DiagReqData7 "Diagnostic signal Data request";
CM_ BO_ 1705 "IDB Diagnostic Request";
CM_ SG_ 1705 IDB_DiagReqData0 "Diagnostic signal Data request";
CM_ SG_ 1705 IDB_DiagReqData1 "Diagnostic signal Data request";
CM_ SG_ 1705 IDB_DiagReqData2 "Diagnostic signal Data request";
CM_ SG_ 1705 IDB_DiagReqData3 "Diagnostic signal Data request";
CM_ SG_ 1705 IDB_DiagReqData4 "Diagnostic signal Data request";
CM_ SG_ 1705 IDB_DiagReqData5 "Diagnostic signal Data request";
CM_ SG_ 1705 IDB_DiagReqData6 "Remote Diagnostic signal Data request";
CM_ SG_ 1705 IDB_DiagReqData7 "Diagnostic signal Data request";
CM_ BO_ 1706 "AVAS Diagnostic Request";
CM_ SG_ 1706 AVAS_DiagReqData0 "Remote Diagnostic signal Data request";
CM_ SG_ 1706 AVAS_DiagReqData1 "Diagnostic signal Data request";
CM_ SG_ 1706 AVAS_DiagReqData2 "Diagnostic signal Data request";
CM_ SG_ 1706 AVAS_DiagReqData3 "Remote Diagnostic signal Data request";
CM_ SG_ 1706 AVAS_DiagReqData4 "Diagnostic signal Data request";
CM_ SG_ 1706 AVAS_DiagReqData5 "Diagnostic signal Data request";
CM_ SG_ 1706 AVAS_DiagReqData6 "Diagnostic signal Data request";
CM_ SG_ 1706 AVAS_DiagReqData7 "Diagnostic signal Data request";
CM_ BO_ 1708 "VCU Diagnostic Request";
CM_ SG_ 1708 VCU_DiagReqData0 "Remote Diagnostic signal Data request";
CM_ SG_ 1708 VCU_DiagReqData1 "Diagnostic signal Data request";
CM_ SG_ 1708 VCU_DiagReqData2 "Remote Diagnostic signal Data request";
CM_ SG_ 1708 VCU_DiagReqData3 "Diagnostic signal Data request";
CM_ SG_ 1708 VCU_DiagReqData4 "Diagnostic signal Data request";
CM_ SG_ 1708 VCU_DiagReqData5 "Remote Diagnostic signal Data request";
CM_ SG_ 1708 VCU_DiagReqData6 "Diagnostic signal Data request";
CM_ SG_ 1708 VCU_DiagReqData7 "Remote Diagnostic signal Data request";
CM_ BO_ 1716 "SRR FR Diagnostic Request";
CM_ SG_ 1716 SRR_FR_DiagReqData0 "SRR_Diagnostic Request";
CM_ SG_ 1716 SRR_FR_DiagReqData1 "SRR_Diagnostic Request";
CM_ SG_ 1716 SRR_FR_DiagReqData2 "Diagnostic signal Data request";
CM_ SG_ 1716 SRR_FR_DiagReqData3 "Diagnostic signal Data request";
CM_ SG_ 1716 SRR_FR_DiagReqData4 "Diagnostic signal Data request";
CM_ SG_ 1716 SRR_FR_DiagReqData5 "SRR_Diagnostic Request";
CM_ SG_ 1716 SRR_FR_DiagReqData6 "Diagnostic signal Data request";
CM_ SG_ 1716 SRR_FR_DiagReqData7 "SRR_Diagnostic Request";
CM_ BO_ 1717 "SRR FL Diagnostic Request";
CM_ SG_ 1717 SRR_FL_DiagReqData0 "Diagnostic signal Data request";
CM_ SG_ 1717 SRR_FL_DiagReqData1 "Diagnostic signal Data request";
CM_ SG_ 1717 SRR_FL_DiagReqData2 "SRR_Diagnostic Request";
CM_ SG_ 1717 SRR_FL_DiagReqData3 "SRR_Diagnostic Request";
CM_ SG_ 1717 SRR_FL_DiagReqData4 "Diagnostic signal Data request";
CM_ SG_ 1717 SRR_FL_DiagReqData5 "Diagnostic signal Data request";
CM_ SG_ 1717 SRR_FL_DiagReqData6 "Diagnostic signal Data request";
CM_ SG_ 1717 SRR_FL_DiagReqData7 "Diagnostic signal Data request";
CM_ BO_ 1718 "SRR RR Diagnostic Request";
CM_ SG_ 1718 SRR_RR_DiagReqData0 "Diagnostic signal Data request";
CM_ SG_ 1718 SRR_RR_DiagReqData1 "SRR_Diagnostic Request";
CM_ SG_ 1718 SRR_RR_DiagReqData2 "Diagnostic signal Data request";
CM_ SG_ 1718 SRR_RR_DiagReqData3 "Diagnostic signal Data request";
CM_ SG_ 1718 SRR_RR_DiagReqData4 "SRR_Diagnostic Request";
CM_ SG_ 1718 SRR_RR_DiagReqData5 "SRR_Diagnostic Request";
CM_ SG_ 1718 SRR_RR_DiagReqData6 "SRR_Diagnostic Request";
CM_ SG_ 1718 SRR_RR_DiagReqData7 "Diagnostic signal Data request";
CM_ BO_ 1719 "SRR RL Diagnostic Request";
CM_ SG_ 1719 SRR_RL_DiagReqData0 "SRR_Diagnostic Request";
CM_ SG_ 1719 SRR_RL_DiagReqData1 "Diagnostic signal Data request";
CM_ SG_ 1719 SRR_RL_DiagReqData2 "Diagnostic signal Data request";
CM_ SG_ 1719 SRR_RL_DiagReqData3 "Diagnostic signal Data request";
CM_ SG_ 1719 SRR_RL_DiagReqData4 "Diagnostic signal Data request";
CM_ SG_ 1719 SRR_RL_DiagReqData5 "SRR_Diagnostic Request";
CM_ SG_ 1719 SRR_RL_DiagReqData6 "Diagnostic signal Data request";
CM_ SG_ 1719 SRR_RL_DiagReqData7 "Diagnostic signal Data request";
CM_ BO_ 1728 "ADAS DiagReq";
CM_ SG_ 1728 ADAS_DiagReqData0 "Diagnostic signal Data request";
CM_ SG_ 1728 ADAS_DiagReqData1 "Diagnostic signal Data request";
CM_ SG_ 1728 ADAS_DiagReqData2 "Diagnostic signal Data request";
CM_ SG_ 1728 ADAS_DiagReqData3 "Diagnostic signal Data request";
CM_ SG_ 1728 ADAS_DiagReqData4 "Diagnostic signal Data request";
CM_ SG_ 1728 ADAS_DiagReqData5 "Diagnostic signal Data request";
CM_ SG_ 1728 ADAS_DiagReqData6 "Diagnostic signal Data request";
CM_ SG_ 1728 ADAS_DiagReqData7 "Diagnostic signal Data request";
CM_ BO_ 1775 "Diagnostic Request for all CAN";
CM_ SG_ 1775 DiagReqAllCANData0 "Diagnostic message Request all CAN";
CM_ SG_ 1775 DiagReqAllCANData1 "Diagnostic message Request all CAN";
CM_ SG_ 1775 DiagReqAllCANData2 "Diagnostic message Request all CAN";
CM_ SG_ 1775 DiagReqAllCANData3 "Diagnostic message Request all CAN";
CM_ SG_ 1775 DiagReqAllCANData4 "Diagnostic message Request all CAN";
CM_ SG_ 1775 DiagReqAllCANData5 "Diagnostic message Request all CAN";
CM_ SG_ 1775 DiagReqAllCANData6 "Diagnostic message Request all CAN";
CM_ SG_ 1775 DiagReqAllCANData7 "Diagnostic message Request all CAN";
CM_ BO_ 1791 "Diagnostic Request for all ECUs";
CM_ SG_ 1791 DiagReqAllEcuData0 "Diagnostic message all ECUs";
CM_ SG_ 1791 DiagReqAllEcuData1 "Diagnostic message all ECUs";
CM_ SG_ 1791 DiagReqAllEcuData2 "Diagnostic message all ECUs";
CM_ SG_ 1791 DiagReqAllEcuData3 "Diagnostic message all ECUs";
CM_ SG_ 1791 DiagReqAllEcuData4 "Diagnostic message all ECUs";
CM_ SG_ 1791 DiagReqAllEcuData5 "Diagnostic message all ECUs";
CM_ SG_ 1791 DiagReqAllEcuData6 "Diagnostic message all ECUs";
CM_ SG_ 1791 DiagReqAllEcuData7 "Diagnostic message all ECUs";
CM_ BO_ 1817 "SEED_CAN_Req16";
CM_ SG_ 1817 SEED_CAN_Req11 "byte 0/1 identifier of target ECU
byte 2/3 service request type 270x/670x
byte 4-7 seed key";
CM_ BO_ 1827 "SEED_CAN_Req18";
CM_ SG_ 1827 SEED_CAN_Req13 "byte 0/1 identifier of target ECU
byte 2/3 service request type 270x/670x
byte 4-7 seed key";
CM_ BO_ 1829 "SEED_CAN_Req20";
CM_ SG_ 1829 SEED_CAN_Req14 "byte 0/1 identifier of target ECU
byte 2/3 service request type 270x/670x
byte 4-7 seed key";
CM_ BO_ 1831 "SEED_CAN_Req22";
CM_ SG_ 1831 SEED_CAN_Req15 "byte 0/1 identifier of target ECU
byte 2/3 service request type 270x/670x
byte 4-7 seed key";
CM_ BO_ 1960 "CCP XCP tool response";
CM_ SG_ 1960 EPS_XCP_CCPRespData0 "XCP_CCP Data response";
CM_ SG_ 1960 EPS_XCP_CCPRespData1 "XCP_CCP Data response";
CM_ SG_ 1960 EPS_XCP_CCPRespData2 "XCP_CCP Data response";
CM_ SG_ 1960 EPS_XCP_CCPRespData3 "XCP_CCP Data response";
CM_ SG_ 1960 EPS_XCP_CCPRespData4 "XCP_CCP Data response";
CM_ SG_ 1960 EPS_XCP_CCPRespData5 "XCP_CCP Data response";
CM_ SG_ 1960 EPS_XCP_CCPRespData6 "XCP_CCP Data response";
CM_ SG_ 1960 EPS_XCP_CCPRespData7 "XCP_CCP Data response";
CM_ BO_ 2007 "CCP XCP tool request";
CM_ SG_ 2007 EPS_XCP_CCPReqData0 "XCP_CCP Data request";
CM_ SG_ 2007 EPS_XCP_CCPReqData1 "XCP_CCP Data request";
CM_ SG_ 2007 EPS_XCP_CCPReqData2 "XCP_CCP Data request";
CM_ SG_ 2007 EPS_XCP_CCPReqData3 "XCP_CCP Data request";
CM_ SG_ 2007 EPS_XCP_CCPReqData4 "XCP_CCP Data request";
CM_ SG_ 2007 EPS_XCP_CCPReqData5 "XCP_CCP Data request";
CM_ SG_ 2007 EPS_XCP_CCPReqData6 "XCP_CCP Data request";
CM_ SG_ 2007 EPS_XCP_CCPReqData7 "XCP_CCP Data request";
CM_ BO_ 2015 "Diagnostic Request for all ECUs";
CM_ SG_ 2015 Diag_Request_ECU_Data0 "Diagnostic message all ECUs";
CM_ SG_ 2015 Diag_Request_ECU_Data1 "Diagnostic message all ECUs";
CM_ SG_ 2015 Diag_Request_ECU_Data2 "Diagnostic message all ECUs";
CM_ SG_ 2015 Diag_Request_ECU_Data3 "Diagnostic message all ECUs";
CM_ SG_ 2015 Diag_Request_ECU_Data4 "Diagnostic message all ECUs";
CM_ SG_ 2015 Diag_Request_ECU_Data5 "Diagnostic message all ECUs";
CM_ SG_ 2015 Diag_Request_ECU_Data6 "Diagnostic message all ECUs";
CM_ SG_ 2015 Diag_Request_ECU_Data7 "Diagnostic message all ECUs";
BA_DEF_ BO_  "GenMsgSendType" ENUM  "Cyclic","NotUsed","NotUsed","NotUsed","NotUsed","NotUsed","NotUsed","IfActive","NoMsgSendType","NotUsed";
BA_DEF_ BO_  "GenMsgILSupport" ENUM  "No","Yes";
BA_DEF_ BO_  "DiagResponse" ENUM  "No","Yes";
BA_DEF_ BO_  "DiagRequest" ENUM  "No","Yes";
BA_DEF_ BO_  "NmAsrMessage" ENUM  "No","Yes";
BA_DEF_ BO_  "DiagState" ENUM  "No","Yes";
BA_DEF_ BO_  "DiagUudtResponse" ENUM  "False","True";
BA_DEF_ BO_  "GenMsgStartDelayTime" INT 0 65535;
BA_DEF_ BO_  "GenMsgDelayTime" INT 0 0;
BA_DEF_ BO_  "GenMsgNrOfRepetition" INT 0 0;
BA_DEF_ BO_  "GenMsgCycleTimeFast" INT 0 0;
BA_DEF_ BO_  "GenMsgCycleTime" INT 0 0;
BA_DEF_ SG_  "GenSigSendType" ENUM  "Cyclic","OnWrite","OnWriteWithRepetition","OnChange","OnChangeWithRepetition","IfActive","IfActiveWithRepetition","NoSigSendType","NotUsed","NotUsed","NotUsed","NotUsed","NotUsed";
BA_DEF_ SG_  "InvalidValue" STRING ;
BA_DEF_ SG_  "GenSigStartValue" INT 0 0;
BA_DEF_ SG_  "GenSigTimeoutTime_ALL" INT 0 65535;
BA_DEF_DEF_  "GenMsgSendType" "NoMsgSendType";
BA_DEF_DEF_  "GenMsgILSupport" "Yes";
BA_DEF_DEF_  "DiagResponse" "No";
BA_DEF_DEF_  "DiagRequest" "No";
BA_DEF_DEF_  "NmAsrMessage" "No";
BA_DEF_DEF_  "DiagState" "No";
BA_DEF_DEF_  "DiagUudtResponse" "False";
BA_DEF_DEF_  "GenMsgStartDelayTime" 0;
BA_DEF_DEF_  "GenMsgDelayTime" 0;
BA_DEF_DEF_  "GenMsgNrOfRepetition" 0;
BA_DEF_DEF_  "GenMsgCycleTimeFast" 0;
BA_DEF_DEF_  "GenMsgCycleTime" 0;
BA_DEF_DEF_  "GenSigSendType" "Cyclic";
BA_DEF_DEF_  "InvalidValue" "";
BA_DEF_DEF_  "GenSigStartValue" 0;
BA_DEF_DEF_  "GenSigTimeoutTime_ALL" 0;
BA_ "GenMsgSendType" BO_ 1039 0;
BA_ "GenMsgCycleTime" BO_ 1039 1000;
BA_ "GenMsgSendType" BO_ 1059 0;
BA_ "GenMsgILSupport" BO_ 1059 0;
BA_ "GenMsgCycleTime" BO_ 1059 1000;
BA_ "GenMsgSendType" BO_ 1060 0;
BA_ "GenMsgILSupport" BO_ 1060 0;
BA_ "GenMsgCycleTime" BO_ 1060 5000;
BA_ "GenMsgSendType" BO_ 1061 0;
BA_ "GenMsgILSupport" BO_ 1061 0;
BA_ "GenMsgCycleTime" BO_ 1061 40;
BA_ "GenMsgSendType" BO_ 1062 0;
BA_ "GenMsgILSupport" BO_ 1062 0;
BA_ "GenMsgCycleTime" BO_ 1062 100;
BA_ "GenMsgSendType" BO_ 1063 0;
BA_ "GenMsgILSupport" BO_ 1063 0;
BA_ "GenMsgCycleTime" BO_ 1063 100;

BA_ "GenMsgCycleTime" BO_ 1064 200;
BA_ "GenMsgSendType" BO_ 1064 0;
BA_ "GenMsgSendType" BO_ 1072 0;
BA_ "GenMsgCycleTime" BO_ 1072 20;
BA_ "GenMsgSendType" BO_ 1074 0;
BA_ "GenMsgCycleTime" BO_ 1074 500;
BA_ "GenMsgSendType" BO_ 1095 0;
BA_ "GenMsgCycleTime" BO_ 1095 200;
BA_ "GenMsgSendType" BO_ 1191 0;
BA_ "GenMsgNrOfRepetition" BO_ 1191 2;
BA_ "GenMsgCycleTimeFast" BO_ 1191 100;
BA_ "GenMsgCycleTime" BO_ 1191 1000;
BA_ "GenMsgSendType" BO_ 1192 0;
BA_ "GenMsgNrOfRepetition" BO_ 1192 2;
BA_ "GenMsgILSupport" BO_ 1192 0;
BA_ "GenMsgCycleTimeFast" BO_ 1192 100;
BA_ "GenMsgCycleTime" BO_ 1192 1000;
BA_ "GenMsgSendType" BO_ 1193 0;
BA_ "GenMsgNrOfRepetition" BO_ 1193 2;
BA_ "GenMsgILSupport" BO_ 1193 0;
BA_ "GenMsgCycleTimeFast" BO_ 1193 100;
BA_ "GenMsgCycleTime" BO_ 1193 1000;
BA_ "NmAsrMessage" BO_ 1282 1;
BA_ "GenMsgSendType" BO_ 1282 0;
BA_ "GenMsgILSupport" BO_ 1282 0;
BA_ "GenMsgCycleTime" BO_ 1282 640;
BA_ "NmAsrMessage" BO_ 1317 1;
BA_ "GenMsgSendType" BO_ 1317 0;
BA_ "GenMsgCycleTime" BO_ 1317 640;
BA_ "NmAsrMessage" BO_ 1321 1;
BA_ "GenMsgSendType" BO_ 1321 0;
BA_ "GenMsgILSupport" BO_ 1321 0;
BA_ "GenMsgCycleTime" BO_ 1321 640;
BA_ "NmAsrMessage" BO_ 1324 1;
BA_ "GenMsgSendType" BO_ 1324 0;
BA_ "GenMsgCycleTime" BO_ 1324 640;
BA_ "NmAsrMessage" BO_ 1344 1;
BA_ "GenMsgSendType" BO_ 1344 0;
BA_ "GenMsgILSupport" BO_ 1344 0;
BA_ "GenMsgCycleTime" BO_ 1344 640;
BA_ "GenMsgILSupport" BO_ 1551 0;
BA_ "DiagResponse" BO_ 1551 1;
BA_ "GenMsgILSupport" BO_ 1573 0;
BA_ "DiagResponse" BO_ 1573 1;
BA_ "GenMsgILSupport" BO_ 1574 0;
BA_ "DiagResponse" BO_ 1574 1;
BA_ "GenMsgILSupport" BO_ 1575 0;
BA_ "DiagResponse" BO_ 1575 1;
BA_ "GenMsgILSupport" BO_ 1576 0;
BA_ "DiagResponse" BO_ 1576 1;
BA_ "DiagResponse" BO_ 1577 1;
BA_ "GenMsgILSupport" BO_ 1578 0;
BA_ "DiagResponse" BO_ 1578 1;
BA_ "DiagResponse" BO_ 1580 1;
BA_ "DiagResponse" BO_ 1588 1;
BA_ "DiagResponse" BO_ 1589 1;
BA_ "DiagResponse" BO_ 1590 1;
BA_ "DiagResponse" BO_ 1591 1;
BA_ "GenMsgILSupport" BO_ 1600 0;
BA_ "DiagResponse" BO_ 1600 1;
BA_ "GenMsgILSupport" BO_ 1679 0;
BA_ "DiagRequest" BO_ 1679 1;
BA_ "GenMsgILSupport" BO_ 1701 0;
BA_ "DiagRequest" BO_ 1701 1;
BA_ "GenMsgILSupport" BO_ 1702 0;
BA_ "DiagRequest" BO_ 1702 1;
BA_ "DiagRequest" BO_ 1703 1;
BA_ "DiagRequest" BO_ 1704 1;
BA_ "DiagRequest" BO_ 1705 1;
BA_ "DiagRequest" BO_ 1706 1;
BA_ "DiagRequest" BO_ 1708 1;
BA_ "GenMsgILSupport" BO_ 1716 0;
BA_ "DiagRequest" BO_ 1716 1;
BA_ "GenMsgILSupport" BO_ 1717 0;
BA_ "DiagRequest" BO_ 1717 1;
BA_ "GenMsgILSupport" BO_ 1718 0;
BA_ "DiagRequest" BO_ 1718 1;
BA_ "GenMsgILSupport" BO_ 1719 0;
BA_ "DiagRequest" BO_ 1719 1;
BA_ "GenMsgILSupport" BO_ 1728 0;
BA_ "DiagRequest" BO_ 1728 1;
BA_ "GenMsgILSupport" BO_ 1775 0;
BA_ "DiagState" BO_ 1775 1;
BA_ "GenMsgILSupport" BO_ 1791 0;
BA_ "DiagState" BO_ 1791 1;
BA_ "DiagResponse" BO_ 1960 1;
BA_ "DiagRequest" BO_ 2007 1;
BA_ "GenMsgILSupport" BO_ 2015 0;
BA_ "DiagState" BO_ 2015 1;
BA_ "GenSigTimeoutTime_ALL" SG_ 1039 CHSKM_YSS_WarnMsg 5000;
BA_ "GenSigSendType" SG_ 1039 CHSKM_YSS_WarnMsg 3;
BA_ "InvalidValue" SG_ 1039 ALV_YSS_WarnMsg "Fh";
BA_ "GenSigTimeoutTime_ALL" SG_ 1039 ALV_YSS_WarnMsg 5000;
BA_ "GenSigSendType" SG_ 1039 ALV_YSS_WarnMsg 4;
BA_ "GenSigTimeoutTime_ALL" SG_ 1039 YSS_Warning_Flag_1 5000;
BA_ "GenSigSendType" SG_ 1039 YSS_Warning_Flag_1 4;
BA_ "GenSigTimeoutTime_ALL" SG_ 1039 YSS_Warning_Flag_2 5000;
BA_ "GenSigSendType" SG_ 1039 YSS_Warning_Flag_2 4;
BA_ "GenSigTimeoutTime_ALL" SG_ 1039 YSS_Warning_Flag_3 5000;
BA_ "GenSigSendType" SG_ 1039 YSS_Warning_Flag_3 4;
BA_ "GenSigTimeoutTime_ALL" SG_ 1039 YSS_Warning_Flag_4 5000;
BA_ "GenSigSendType" SG_ 1039 YSS_Warning_Flag_4 4;
BA_ "GenSigTimeoutTime_ALL" SG_ 1039 YSS_Warning_Flag_5 5000;
BA_ "GenSigSendType" SG_ 1039 YSS_Warning_Flag_5 4;
BA_ "GenSigTimeoutTime_ALL" SG_ 1039 YSS_Warning_Flag_6 5000;
BA_ "GenSigSendType" SG_ 1039 YSS_Warning_Flag_6 4;
BA_ "GenSigTimeoutTime_ALL" SG_ 1039 YSS_Warning_Flag_7 5000;
BA_ "GenSigSendType" SG_ 1039 YSS_Warning_Flag_7 4;
BA_ "GenSigTimeoutTime_ALL" SG_ 1039 YSS_Warning_Flag_8 5000;
BA_ "GenSigSendType" SG_ 1039 YSS_Warning_Flag_8 4;
BA_ "GenSigTimeoutTime_ALL" SG_ 1039 YSS_Warning_Flag_9 5000;
BA_ "GenSigSendType" SG_ 1039 YSS_Warning_Flag_9 4;
BA_ "GenSigTimeoutTime_ALL" SG_ 1039 YSS_Warning_Flag_10 5000;
BA_ "GenSigSendType" SG_ 1039 YSS_Warning_Flag_10 4;
BA_ "GenSigTimeoutTime_ALL" SG_ 1039 YSS_Warning_Flag_11 5000;
BA_ "GenSigSendType" SG_ 1039 YSS_Warning_Flag_11 4;
BA_ "GenSigTimeoutTime_ALL" SG_ 1039 YSS_Warning_Flag_12 5000;
BA_ "GenSigSendType" SG_ 1039 YSS_Warning_Flag_12 4;
BA_ "GenSigTimeoutTime_ALL" SG_ 1039 YSS_Reserved_signal1 5000;
BA_ "GenSigSendType" SG_ 1039 YSS_Reserved_signal1 4;
BA_ "GenSigTimeoutTime_ALL" SG_ 1039 YSS_Reserved_signal2 5000;
BA_ "GenSigSendType" SG_ 1039 YSS_Reserved_signal2 4;
BA_ "GenSigTimeoutTime_ALL" SG_ 1039 YSS_Reserved_signal3 5000;
BA_ "GenSigSendType" SG_ 1039 YSS_Reserved_signal3 4;
BA_ "GenSigTimeoutTime_ALL" SG_ 1039 YSS_Reserved_signal4 5000;
BA_ "GenSigSendType" SG_ 1039 YSS_Reserved_signal4 4;
BA_ "GenSigTimeoutTime_ALL" SG_ 1039 YSS_Reserved_signal5 5000;
BA_ "GenSigSendType" SG_ 1039 YSS_Reserved_signal5 4;
BA_ "GenSigTimeoutTime_ALL" SG_ 1059 AVAS_BatteryUnderVoltage 5000;
BA_ "GenSigTimeoutTime_ALL" SG_ 1059 AVAS_BatteryOverVoltage 5000;
BA_ "GenSigTimeoutTime_ALL" SG_ 1059 AVAS_VINInfoNotPrgm 5000;
BA_ "GenSigTimeoutTime_ALL" SG_ 1059 AVAS_AMPVoltSplDrvOperationFail 5000;
BA_ "GenSigTimeoutTime_ALL" SG_ 1059 AVAS_AMPIntFaultOverCurr 5000;
BA_ "GenSigTimeoutTime_ALL" SG_ 1059 AVAS_AMPInternalFaultDCError 5000;
BA_ "GenSigTimeoutTime_ALL" SG_ 1059 AVAS_AMPInternalFaultOverTemp 5000;
BA_ "GenSigTimeoutTime_ALL" SG_ 1059 AVAS_AMPInternalFaultClockError 5000;
BA_ "GenSigTimeoutTime_ALL" SG_ 1059 AVAS_SpkrMntPwrSwDrvHighFlt 5000;
BA_ "GenSigTimeoutTime_ALL" SG_ 1059 AVAS_SpkrMntPwrSwDrvLowFlt 5000;
BA_ "GenSigTimeoutTime_ALL" SG_ 1059 AVAS_InternalSpeakerOpen 5000;
BA_ "GenSigTimeoutTime_ALL" SG_ 1059 AVAS_ECUMalFlshOperationErr 5000;
BA_ "GenSigTimeoutTime_ALL" SG_ 1059 AVAS_ECUMalfunctionRamFailure 5000;
BA_ "GenSigTimeoutTime_ALL" SG_ 1059 AVAS_ECUMalEEPROMFailure 5000;
BA_ "GenSigTimeoutTime_ALL" SG_ 1059 AVAS_CANBusOff 5000;
BA_ "GenSigTimeoutTime_ALL" SG_ 1059 AVAS_LossCommVehicleSpeed 5000;
BA_ "GenSigTimeoutTime_ALL" SG_ 1059 AVAS_LossCommGearPosition 5000;
BA_ "GenSigTimeoutTime_ALL" SG_ 1059 AVAS_LossCommAVASCloseCmd 5000;
BA_ "GenSigTimeoutTime_ALL" SG_ 1060 AVAS_SWNumber 25000;
BA_ "GenSigTimeoutTime_ALL" SG_ 1060 AVAS_HWNumber 25000;
BA_ "GenSigTimeoutTime_ALL" SG_ 1060 AVAS_MXNumber 25000;
BA_ "InvalidValue" SG_ 1061 ActualGearShiftPosition "7h";
BA_ "GenSigTimeoutTime_ALL" SG_ 1061 ActualGearShiftPosition 400;
BA_ "GenSigStartValue" SG_ 1061 ActualGearShiftPosition 7;
BA_ "InvalidValue" SG_ 1062 ESP_VehicleSpeed "1FFFh";
BA_ "GenSigTimeoutTime_ALL" SG_ 1062 ESP_VehicleSpeed 500;
BA_ "GenSigTimeoutTime_ALL" SG_ 1062 VCU_STAT_Terminal_BEV 500;
BA_ "GenSigTimeoutTime_ALL" SG_ 1063 IPC_AVASCloseCmd 500;
BA_ "GenSigTimeoutTime_ALL" SG_ 1064 BCM_Keyfob_Leftcar 5000;
BA_ "GenSigSendType" SG_ 1064 BCM_Keyfob_Leftcar 4;
BA_ "InvalidValue" SG_ 1064 TRMFitted "3";
BA_ "GenSigTimeoutTime_ALL" SG_ 1064 TRMFitted 1000;
BA_ "GenSigStartValue" SG_ 1064 TRMFitted 2;
BA_ "GenSigTimeoutTime_ALL" SG_ 1072 ADAS_DMS_Checksum 200;
BA_ "InvalidValue" SG_ 1072 ADAS_DMS_Alive "Fh";
BA_ "GenSigTimeoutTime_ALL" SG_ 1072 ADAS_DMS_Alive 200;
BA_ "GenSigTimeoutTime_ALL" SG_ 1072 ADAS_DMS_HapWarning 200;
BA_ "GenSigTimeoutTime_ALL" SG_ 1074 MHU_FOTA_Checksum 2500;
BA_ "InvalidValue" SG_ 1074 MHU_FOTA_Alive_Counter "Fh";
BA_ "GenSigTimeoutTime_ALL" SG_ 1074 MHU_FOTA_Alive_Counter 2500;
BA_ "InvalidValue" SG_ 1074 MHU_FOTA_State "7h";
BA_ "GenSigTimeoutTime_ALL" SG_ 1074 MHU_FOTA_State 2500;
BA_ "GenSigTimeoutTime_ALL" SG_ 1074 MHU_FOTA_Error_Code 2500;
BA_ "GenSigTimeoutTime_ALL" SG_ 1095 CHKSM_MHU_SET_CarMode 1000;
BA_ "InvalidValue" SG_ 1095 ALV_MHU_SET_CarMode "Fh";
BA_ "GenSigTimeoutTime_ALL" SG_ 1095 ALV_MHU_SET_CarMode 1000;
BA_ "InvalidValue" SG_ 1095 MHU_Request_CarOFF "3h";
BA_ "GenSigTimeoutTime_ALL" SG_ 1095 MHU_Request_CarOFF 1000;
BA_ "InvalidValue" SG_ 1095 MHU_SET_ChildMode "3h";
BA_ "GenSigTimeoutTime_ALL" SG_ 1095 MHU_SET_ChildMode 1000;
BA_ "InvalidValue" SG_ 1095 MHU_SET_GameMode "3h";
BA_ "GenSigTimeoutTime_ALL" SG_ 1095 MHU_SET_GameMode 1000;
BA_ "InvalidValue" SG_ 1095 MHU_SET_KaraokeMode "3h";
BA_ "GenSigTimeoutTime_ALL" SG_ 1095 MHU_SET_KaraokeMode 1000;
BA_ "InvalidValue" SG_ 1095 MHU_SET_WashMode "3h";
BA_ "GenSigTimeoutTime_ALL" SG_ 1095 MHU_SET_WashMode 1000;
BA_ "InvalidValue" SG_ 1095 MHU_SET_StopMode "7h";
BA_ "GenSigTimeoutTime_ALL" SG_ 1095 MHU_SET_StopMode 1000;
BA_ "GenSigTimeoutTime_ALL" SG_ 1191 CHSKM_RCU_WarnMsg 5000;
BA_ "GenSigSendType" SG_ 1191 CHSKM_RCU_WarnMsg 3;
BA_ "InvalidValue" SG_ 1191 ALV_RCU_WarnMsg "Fh";
BA_ "GenSigTimeoutTime_ALL" SG_ 1191 ALV_RCU_WarnMsg 5000;
BA_ "GenSigSendType" SG_ 1191 ALV_RCU_WarnMsg 3;
BA_ "GenSigTimeoutTime_ALL" SG_ 1191 RCU_DAA_NoOpDoorOpen 5000;
BA_ "GenSigSendType" SG_ 1191 RCU_DAA_NoOpDoorOpen 4;
BA_ "GenSigTimeoutTime_ALL" SG_ 1191 RCU_EHandBrk_fault 5000;
BA_ "GenSigSendType" SG_ 1191 RCU_EHandBrk_fault 4;
BA_ "GenSigTimeoutTime_ALL" SG_ 1191 RCU_EOL_NotDone 5000;
BA_ "GenSigSendType" SG_ 1191 RCU_EOL_NotDone 4;
BA_ "GenSigTimeoutTime_ALL" SG_ 1191 RCU_ECD_RWU_active 5000;
BA_ "GenSigSendType" SG_ 1191 RCU_ECD_RWU_active 4;
BA_ "GenSigTimeoutTime_ALL" SG_ 1191 RCU_ParkOnSteepInclination 5000;
BA_ "GenSigSendType" SG_ 1191 RCU_ParkOnSteepInclination 4;
BA_ "GenSigTimeoutTime_ALL" SG_ 1191 RCU_BrkForceNotEnough 5000;
BA_ "GenSigSendType" SG_ 1191 RCU_BrkForceNotEnough 4;
BA_ "GenSigTimeoutTime_ALL" SG_ 1191 RCU_ReleaseEPB_Wo_PressBrk 5000;
BA_ "GenSigSendType" SG_ 1191 RCU_ReleaseEPB_Wo_PressBrk 4;
BA_ "GenSigTimeoutTime_ALL" SG_ 1191 RCU_ParkBrkApplied 5000;
BA_ "GenSigSendType" SG_ 1191 RCU_ParkBrkApplied 4;
BA_ "GenSigTimeoutTime_ALL" SG_ 1191 RCU_Swch_Mafnc 5000;
BA_ "GenSigSendType" SG_ 1191 RCU_Swch_Mafnc 4;
BA_ "GenSigTimeoutTime_ALL" SG_ 1191 RCU_DAA_NoOpBeltUnbuckled 5000;
BA_ "GenSigSendType" SG_ 1191 RCU_DAA_NoOpBeltUnbuckled 4;
BA_ "GenSigTimeoutTime_ALL" SG_ 1191 RCU_RollerBenchMode 5000;
BA_ "GenSigSendType" SG_ 1191 RCU_RollerBenchMode 4;
BA_ "GenSigTimeoutTime_ALL" SG_ 1191 RCU_EPB_ParkLampState 5000;
BA_ "GenSigSendType" SG_ 1191 RCU_EPB_ParkLampState 4;
BA_ "GenSigTimeoutTime_ALL" SG_ 1191 RCU_EPB_WarnLampState 5000;
BA_ "GenSigSendType" SG_ 1191 RCU_EPB_WarnLampState 4;
BA_ "GenSigTimeoutTime_ALL" SG_ 1191 RCU_WflagRes36 5000;
BA_ "GenSigSendType" SG_ 1191 RCU_WflagRes36 4;
BA_ "GenSigTimeoutTime_ALL" SG_ 1191 RCU_WflagRes37 5000;
BA_ "GenSigSendType" SG_ 1191 RCU_WflagRes37 4;
BA_ "GenSigTimeoutTime_ALL" SG_ 1191 RCU_WflagRes38 5000;
BA_ "GenSigSendType" SG_ 1191 RCU_WflagRes38 4;
BA_ "GenSigTimeoutTime_ALL" SG_ 1191 RCU_WflagRes39 5000;
BA_ "GenSigSendType" SG_ 1191 RCU_WflagRes39 4;
BA_ "GenSigTimeoutTime_ALL" SG_ 1191 RCU_WflagRes40 5000;
BA_ "GenSigSendType" SG_ 1191 RCU_WflagRes40 4;
BA_ "GenSigTimeoutTime_ALL" SG_ 1191 RCU_WflagRes41 5000;
BA_ "GenSigSendType" SG_ 1191 RCU_WflagRes41 4;
BA_ "GenSigTimeoutTime_ALL" SG_ 1191 RCU_WflagRes42 5000;
BA_ "GenSigSendType" SG_ 1191 RCU_WflagRes42 4;
BA_ "GenSigTimeoutTime_ALL" SG_ 1191 RCU_WflagRes43 5000;
BA_ "GenSigSendType" SG_ 1191 RCU_WflagRes43 4;
BA_ "GenSigTimeoutTime_ALL" SG_ 1191 RCU_WflagRes44 5000;
BA_ "GenSigSendType" SG_ 1191 RCU_WflagRes44 4;
BA_ "GenSigTimeoutTime_ALL" SG_ 1191 RCU_WflagRes45 5000;
BA_ "GenSigSendType" SG_ 1191 RCU_WflagRes45 4;
BA_ "GenSigTimeoutTime_ALL" SG_ 1191 RCU_WflagRes46 5000;
BA_ "GenSigSendType" SG_ 1191 RCU_WflagRes46 4;
BA_ "GenSigTimeoutTime_ALL" SG_ 1191 RCU_WflagRes47 5000;
BA_ "GenSigSendType" SG_ 1191 RCU_WflagRes47 4;
BA_ "GenSigTimeoutTime_ALL" SG_ 1191 RCU_Reserved_signal1 5000;
BA_ "GenSigSendType" SG_ 1191 RCU_Reserved_signal1 4;
BA_ "GenSigTimeoutTime_ALL" SG_ 1192 CHSKM_EPS_WarnMsg 5000;
BA_ "GenSigSendType" SG_ 1192 CHSKM_EPS_WarnMsg 3;
BA_ "InvalidValue" SG_ 1192 ALV_EPS_WarnMsg "Fh";
BA_ "GenSigTimeoutTime_ALL" SG_ 1192 ALV_EPS_WarnMsg 5000;
BA_ "GenSigSendType" SG_ 1192 ALV_EPS_WarnMsg 3;
BA_ "GenSigTimeoutTime_ALL" SG_ 1192 EPS_Malfunction 5000;
BA_ "GenSigSendType" SG_ 1192 EPS_Malfunction 4;
BA_ "GenSigTimeoutTime_ALL" SG_ 1192 EPS_Reduced 5000;
BA_ "GenSigSendType" SG_ 1192 EPS_Reduced 4;
BA_ "GenSigTimeoutTime_ALL" SG_ 1192 EPS_Overheat 5000;
BA_ "GenSigSendType" SG_ 1192 EPS_Overheat 4;
BA_ "GenSigTimeoutTime_ALL" SG_ 1192 EPS_NotReady 5000;
BA_ "GenSigSendType" SG_ 1192 EPS_NotReady 4;
BA_ "GenSigTimeoutTime_ALL" SG_ 1192 EPS_Warning_Flag_5 5000;
BA_ "GenSigSendType" SG_ 1192 EPS_Warning_Flag_5 4;
BA_ "GenSigTimeoutTime_ALL" SG_ 1192 EPS_Warning_Flag_6 5000;
BA_ "GenSigSendType" SG_ 1192 EPS_Warning_Flag_6 4;
BA_ "GenSigTimeoutTime_ALL" SG_ 1192 EPS_Warning_Flag_7 5000;
BA_ "GenSigSendType" SG_ 1192 EPS_Warning_Flag_7 4;
BA_ "GenSigTimeoutTime_ALL" SG_ 1192 EPS_Warning_Flag_8 5000;
BA_ "GenSigSendType" SG_ 1192 EPS_Warning_Flag_8 4;
BA_ "GenSigTimeoutTime_ALL" SG_ 1192 EPS_Warning_Flag_9 5000;
BA_ "GenSigSendType" SG_ 1192 EPS_Warning_Flag_9 4;
BA_ "GenSigTimeoutTime_ALL" SG_ 1192 EPS_Warning_Flag_10 5000;
BA_ "GenSigSendType" SG_ 1192 EPS_Warning_Flag_10 4;
BA_ "GenSigTimeoutTime_ALL" SG_ 1192 EPS_Warning_Flag_11 5000;
BA_ "GenSigSendType" SG_ 1192 EPS_Warning_Flag_11 4;
BA_ "GenSigTimeoutTime_ALL" SG_ 1192 EPS_Warning_Flag_12 5000;
BA_ "GenSigSendType" SG_ 1192 EPS_Warning_Flag_12 4;
BA_ "GenSigTimeoutTime_ALL" SG_ 1192 EPS_Reserved_signal1 5000;
BA_ "GenSigSendType" SG_ 1192 EPS_Reserved_signal1 4;
BA_ "GenSigTimeoutTime_ALL" SG_ 1192 EPS_Reserved_signal2 5000;
BA_ "GenSigSendType" SG_ 1192 EPS_Reserved_signal2 4;
BA_ "GenSigTimeoutTime_ALL" SG_ 1192 EPS_Reserved_signal3 5000;
BA_ "GenSigSendType" SG_ 1192 EPS_Reserved_signal3 4;
BA_ "GenSigTimeoutTime_ALL" SG_ 1192 EPS_Reserved_signal4 5000;
BA_ "GenSigSendType" SG_ 1192 EPS_Reserved_signal4 4;
BA_ "GenSigTimeoutTime_ALL" SG_ 1192 EPS_Reserved_signal5 5000;
BA_ "GenSigSendType" SG_ 1192 EPS_Reserved_signal5 4;
BA_ "GenSigTimeoutTime_ALL" SG_ 1193 CHSKM_IDB_WarnMsg 5000;
BA_ "GenSigSendType" SG_ 1193 CHSKM_IDB_WarnMsg 3;
BA_ "InvalidValue" SG_ 1193 ALV_IDB_WarnMsg "Fh";
BA_ "GenSigTimeoutTime_ALL" SG_ 1193 ALV_IDB_WarnMsg 5000;
BA_ "GenSigSendType" SG_ 1193 ALV_IDB_WarnMsg 3;
BA_ "GenSigTimeoutTime_ALL" SG_ 1193 IDB_ESC_fault 5000;
BA_ "GenSigSendType" SG_ 1193 IDB_ESC_fault 4;
BA_ "GenSigTimeoutTime_ALL" SG_ 1193 IDB_ABS_fault 5000;
BA_ "GenSigSendType" SG_ 1193 IDB_ABS_fault 4;
BA_ "GenSigTimeoutTime_ALL" SG_ 1193 IDB_BrkLowFluid 5000;
BA_ "GenSigSendType" SG_ 1193 IDB_BrkLowFluid 4;
BA_ "GenSigTimeoutTime_ALL" SG_ 1193 IDB_BrkSysFault 5000;
BA_ "GenSigSendType" SG_ 1193 IDB_BrkSysFault 4;
BA_ "GenSigTimeoutTime_ALL" SG_ 1193 IDB_fault 5000;
BA_ "GenSigSendType" SG_ 1193 IDB_fault 4;
BA_ "GenSigTimeoutTime_ALL" SG_ 1193 IDB_HydraulicBrkAssist_Fault 5000;
BA_ "GenSigSendType" SG_ 1193 IDB_HydraulicBrkAssist_Fault 4;
BA_ "GenSigTimeoutTime_ALL" SG_ 1193 IDB_HAS_Fault 5000;
BA_ "GenSigSendType" SG_ 1193 IDB_HAS_Fault 4;
BA_ "GenSigTimeoutTime_ALL" SG_ 1193 IDB_TSM_Fault 5000;
BA_ "GenSigSendType" SG_ 1193 IDB_TSM_Fault 4;
BA_ "GenSigTimeoutTime_ALL" SG_ 1193 IDB_Reserved_signal2 5000;
BA_ "GenSigSendType" SG_ 1193 IDB_Reserved_signal2 4;
BA_ "GenSigTimeoutTime_ALL" SG_ 1193 IDB_Reserved_signal3 5000;
BA_ "GenSigSendType" SG_ 1193 IDB_Reserved_signal3 4;
BA_ "GenSigTimeoutTime_ALL" SG_ 1193 IDB_Reserved_signal4 5000;
BA_ "GenSigSendType" SG_ 1193 IDB_Reserved_signal4 4;
BA_ "GenSigTimeoutTime_ALL" SG_ 1193 IDB_Reserved_signal5 5000;
BA_ "GenSigSendType" SG_ 1193 IDB_Reserved_signal5 4;
BA_ "InvalidValue" SG_ 1282 XGW_srcNodeID "FFh";
BA_ "GenSigTimeoutTime_ALL" SG_ 1282 XGW_srcNodeID 2000;
BA_ "GenSigTimeoutTime_ALL" SG_ 1282 XGW_CtrlBitVector 2000;
BA_ "GenSigTimeoutTime_ALL" SG_ 1282 XGW_usrData0 2000;
BA_ "GenSigStartValue" SG_ 1282 XGW_usrData0 255;
BA_ "GenSigTimeoutTime_ALL" SG_ 1282 XGW_usrData1 2000;
BA_ "GenSigStartValue" SG_ 1282 XGW_usrData1 255;
BA_ "GenSigTimeoutTime_ALL" SG_ 1282 XGW_usrData2 2000;
BA_ "GenSigStartValue" SG_ 1282 XGW_usrData2 255;
BA_ "GenSigTimeoutTime_ALL" SG_ 1282 XGW_usrData3 2000;
BA_ "GenSigStartValue" SG_ 1282 XGW_usrData3 255;
BA_ "GenSigTimeoutTime_ALL" SG_ 1282 XGW_usrData4 2000;
BA_ "GenSigStartValue" SG_ 1282 XGW_usrData4 255;
BA_ "GenSigTimeoutTime_ALL" SG_ 1282 XGW_usrData5 2000;
BA_ "GenSigStartValue" SG_ 1282 XGW_usrData5 255;
BA_ "InvalidValue" SG_ 1317 RCU_srcNodeID "FFh";
BA_ "GenSigTimeoutTime_ALL" SG_ 1317 RCU_srcNodeID 2000;
BA_ "GenSigTimeoutTime_ALL" SG_ 1317 RCU_usrData0 2000;
BA_ "GenSigTimeoutTime_ALL" SG_ 1317 RCU_usrData1 2000;
BA_ "GenSigTimeoutTime_ALL" SG_ 1317 RCU_usrData2 2000;
BA_ "GenSigTimeoutTime_ALL" SG_ 1317 RCU_usrData3 2000;
BA_ "GenSigTimeoutTime_ALL" SG_ 1317 RCU_usrData4 2000;
BA_ "GenSigTimeoutTime_ALL" SG_ 1317 RCU_usrData5 2000;
BA_ "InvalidValue" SG_ 1321 IDB_srcNodeID "FFh";
BA_ "GenSigTimeoutTime_ALL" SG_ 1321 IDB_srcNodeID 2000;
BA_ "GenSigTimeoutTime_ALL" SG_ 1321 IDB_CtrlBitVector 2000;
BA_ "GenSigTimeoutTime_ALL" SG_ 1321 IDB_usrData0 2000;
BA_ "GenSigStartValue" SG_ 1321 IDB_usrData0 255;
BA_ "GenSigTimeoutTime_ALL" SG_ 1321 IDB_usrData1 2000;
BA_ "GenSigStartValue" SG_ 1321 IDB_usrData1 255;
BA_ "GenSigTimeoutTime_ALL" SG_ 1321 IDB_usrData2 2000;
BA_ "GenSigStartValue" SG_ 1321 IDB_usrData2 255;
BA_ "GenSigTimeoutTime_ALL" SG_ 1321 IDB_usrData3 2000;
BA_ "GenSigStartValue" SG_ 1321 IDB_usrData3 255;
BA_ "GenSigTimeoutTime_ALL" SG_ 1321 IDB_usrData4 2000;
BA_ "GenSigStartValue" SG_ 1321 IDB_usrData4 255;
BA_ "GenSigTimeoutTime_ALL" SG_ 1321 IDB_usrData5 2000;
BA_ "GenSigStartValue" SG_ 1321 IDB_usrData5 255;
BA_ "InvalidValue" SG_ 1324 VCU_srcNodeID "FFh";
BA_ "GenSigTimeoutTime_ALL" SG_ 1324 VCU_srcNodeID 2000;
BA_ "GenSigTimeoutTime_ALL" SG_ 1324 VCU_CtrlBitVector 2000;
BA_ "GenSigTimeoutTime_ALL" SG_ 1324 VCU_usrData0 2000;
BA_ "GenSigStartValue" SG_ 1324 VCU_usrData0 255;
BA_ "GenSigTimeoutTime_ALL" SG_ 1324 VCU_usrData1 2000;
BA_ "GenSigStartValue" SG_ 1324 VCU_usrData1 255;
BA_ "GenSigTimeoutTime_ALL" SG_ 1324 VCU_usrData2 2000;
BA_ "GenSigStartValue" SG_ 1324 VCU_usrData2 255;
BA_ "GenSigTimeoutTime_ALL" SG_ 1324 VCU_usrData3 2000;
BA_ "GenSigStartValue" SG_ 1324 VCU_usrData3 255;
BA_ "GenSigTimeoutTime_ALL" SG_ 1324 VCU_usrData4 2000;
BA_ "GenSigStartValue" SG_ 1324 VCU_usrData4 255;
BA_ "GenSigTimeoutTime_ALL" SG_ 1324 VCU_usrData5 2000;
BA_ "GenSigStartValue" SG_ 1324 VCU_usrData5 255;
BA_ "InvalidValue" SG_ 1344 ADAS_srcNodeID "FFh";
BA_ "GenSigTimeoutTime_ALL" SG_ 1344 ADAS_srcNodeID 2000;
BA_ "GenSigTimeoutTime_ALL" SG_ 1344 ADAS_CtrlBitVector 2000;
BA_ "GenSigTimeoutTime_ALL" SG_ 1344 ADAS_usrData0 2000;
BA_ "GenSigStartValue" SG_ 1344 ADAS_usrData0 255;
BA_ "GenSigTimeoutTime_ALL" SG_ 1344 ADAS_usrData1 2000;
BA_ "GenSigStartValue" SG_ 1344 ADAS_usrData1 255;
BA_ "GenSigTimeoutTime_ALL" SG_ 1344 ADAS_usrData2 2000;
BA_ "GenSigStartValue" SG_ 1344 ADAS_usrData2 255;
BA_ "GenSigTimeoutTime_ALL" SG_ 1344 ADAS_usrData3 2000;
BA_ "GenSigStartValue" SG_ 1344 ADAS_usrData3 255;
BA_ "GenSigTimeoutTime_ALL" SG_ 1344 ADAS_usrData4 2000;
BA_ "GenSigStartValue" SG_ 1344 ADAS_usrData4 255;
BA_ "GenSigTimeoutTime_ALL" SG_ 1344 ADAS_usrData5 2000;
BA_ "GenSigStartValue" SG_ 1344 ADAS_usrData5 255;
BA_ "GenSigSendType" SG_ 1551 YSS_DiagRespData0 7;
BA_ "GenSigSendType" SG_ 1551 YSS_DiagRespData1 7;
BA_ "GenSigSendType" SG_ 1551 YSS_DiagRespData2 7;
BA_ "GenSigSendType" SG_ 1551 YSS_DiagRespData3 7;
BA_ "GenSigSendType" SG_ 1551 YSS_DiagRespData4 7;
BA_ "GenSigSendType" SG_ 1551 YSS_DiagRespData5 7;
BA_ "GenSigSendType" SG_ 1551 YSS_DiagRespData6 7;
BA_ "GenSigSendType" SG_ 1551 YSS_DiagRespData7 7;
BA_ "GenSigSendType" SG_ 1573 MRGEN_DiagRespData0 7;
BA_ "GenSigSendType" SG_ 1573 MRGEN_DiagRespData1 7;
BA_ "GenSigSendType" SG_ 1573 MRGEN_DiagRespData2 7;
BA_ "GenSigSendType" SG_ 1573 MRGEN_DiagRespData3 7;
BA_ "GenSigSendType" SG_ 1573 MRGEN_DiagRespData4 7;
BA_ "GenSigSendType" SG_ 1573 MRGEN_DiagRespData5 7;
BA_ "GenSigSendType" SG_ 1573 MRGEN_DiagRespData6 7;
BA_ "GenSigSendType" SG_ 1573 MRGEN_DiagRespData7 7;
BA_ "GenSigSendType" SG_ 1574 SCAM_DiagRespData0 7;
BA_ "GenSigSendType" SG_ 1574 SCAM_DiagRespData1 7;
BA_ "GenSigSendType" SG_ 1574 SCAM_DiagRespData2 7;
BA_ "GenSigSendType" SG_ 1574 SCAM_DiagRespData3 7;
BA_ "GenSigSendType" SG_ 1574 SCAM_DiagRespData4 7;
BA_ "GenSigSendType" SG_ 1574 SCAM_DiagRespData5 7;
BA_ "GenSigSendType" SG_ 1574 SCAM_DiagRespData6 7;
BA_ "GenSigSendType" SG_ 1574 SCAM_DiagRespData7 7;
BA_ "GenSigSendType" SG_ 1575 RCU_DiagRespData0 7;
BA_ "GenSigSendType" SG_ 1575 RCU_DiagRespData1 7;
BA_ "GenSigSendType" SG_ 1575 RCU_DiagRespData2 7;
BA_ "GenSigSendType" SG_ 1575 RCU_DiagRespData3 7;
BA_ "GenSigSendType" SG_ 1575 RCU_DiagRespData4 7;
BA_ "GenSigSendType" SG_ 1575 RCU_DiagRespData5 7;
BA_ "GenSigSendType" SG_ 1575 RCU_DiagRespData6 7;
BA_ "GenSigSendType" SG_ 1575 RCU_DiagRespData7 7;
BA_ "GenSigSendType" SG_ 1576 EPS_DiagRespData0 7;
BA_ "GenSigSendType" SG_ 1576 EPS_DiagRespData1 7;
BA_ "GenSigSendType" SG_ 1576 EPS_DiagRespData2 7;
BA_ "GenSigSendType" SG_ 1576 EPS_DiagRespData3 7;
BA_ "GenSigSendType" SG_ 1576 EPS_DiagRespData4 7;
BA_ "GenSigSendType" SG_ 1576 EPS_DiagRespData5 7;
BA_ "GenSigSendType" SG_ 1576 EPS_DiagRespData6 7;
BA_ "GenSigSendType" SG_ 1576 EPS_DiagRespData7 7;
BA_ "GenSigSendType" SG_ 1577 IDB_DiagRespData0 7;
BA_ "GenSigSendType" SG_ 1577 IDB_DiagRespData1 7;
BA_ "GenSigSendType" SG_ 1577 IDB_DiagRespData2 7;
BA_ "GenSigSendType" SG_ 1577 IDB_DiagRespData3 7;
BA_ "GenSigSendType" SG_ 1577 IDB_DiagRespData4 7;
BA_ "GenSigSendType" SG_ 1577 IDB_DiagRespData5 7;
BA_ "GenSigSendType" SG_ 1577 IDB_DiagRespData6 7;
BA_ "GenSigSendType" SG_ 1577 IDB_DiagRespData7 7;
BA_ "GenSigSendType" SG_ 1578 AVAS_DiagRespData0 7;
BA_ "GenSigSendType" SG_ 1578 AVAS_DiagRespData1 7;
BA_ "GenSigSendType" SG_ 1578 AVAS_DiagRespData2 7;
BA_ "GenSigSendType" SG_ 1578 AVAS_DiagRespData3 7;
BA_ "GenSigSendType" SG_ 1578 AVAS_DiagRespData4 7;
BA_ "GenSigSendType" SG_ 1578 AVAS_DiagRespData5 7;
BA_ "GenSigSendType" SG_ 1578 AVAS_DiagRespData6 7;
BA_ "GenSigSendType" SG_ 1578 AVAS_DiagRespData7 7;
BA_ "GenSigSendType" SG_ 1580 VCU_DiagRespData0 7;
BA_ "GenSigSendType" SG_ 1580 VCU_DiagRespData1 7;
BA_ "GenSigSendType" SG_ 1580 VCU_DiagRespData2 7;
BA_ "GenSigSendType" SG_ 1580 VCU_DiagRespData3 7;
BA_ "GenSigSendType" SG_ 1580 VCU_DiagRespData4 7;
BA_ "GenSigSendType" SG_ 1580 VCU_DiagRespData5 7;
BA_ "GenSigSendType" SG_ 1580 VCU_DiagRespData6 7;
BA_ "GenSigSendType" SG_ 1580 VCU_DiagRespData7 7;
BA_ "GenSigSendType" SG_ 1588 SRR_FR_DiagRespData0 7;
BA_ "GenSigSendType" SG_ 1588 SRR_FR_DiagRespData1 7;
BA_ "GenSigSendType" SG_ 1588 SRR_FR_DiagRespData2 7;
BA_ "GenSigSendType" SG_ 1588 SRR_FR_DiagRespData3 7;
BA_ "GenSigSendType" SG_ 1588 SRR_FR_DiagRespData4 7;
BA_ "GenSigSendType" SG_ 1588 SRR_FR_DiagRespData5 7;
BA_ "GenSigSendType" SG_ 1588 SRR_FR_DiagRespData6 7;
BA_ "GenSigSendType" SG_ 1588 SRR_FR_DiagRespData7 7;
BA_ "GenSigSendType" SG_ 1589 SRR_FL_DiagRespData0 7;
BA_ "GenSigSendType" SG_ 1589 SRR_FL_DiagRespData1 7;
BA_ "GenSigSendType" SG_ 1589 SRR_FL_DiagRespData2 7;
BA_ "GenSigSendType" SG_ 1589 SRR_FL_DiagRespData3 7;
BA_ "GenSigSendType" SG_ 1589 SRR_FL_DiagRespData4 7;
BA_ "GenSigSendType" SG_ 1589 SRR_FL_DiagRespData5 7;
BA_ "GenSigSendType" SG_ 1589 SRR_FL_DiagRespData6 7;
BA_ "GenSigSendType" SG_ 1589 SRR_FL_DiagRespData7 7;
BA_ "GenSigSendType" SG_ 1590 SRR_RR_DiagRespData0 7;
BA_ "GenSigSendType" SG_ 1590 SRR_RR_DiagRespData1 7;
BA_ "GenSigSendType" SG_ 1590 SRR_RR_DiagRespData2 7;
BA_ "GenSigSendType" SG_ 1590 SRR_RR_DiagRespData3 7;
BA_ "GenSigSendType" SG_ 1590 SRR_RR_DiagRespData4 7;
BA_ "GenSigSendType" SG_ 1590 SRR_RR_DiagRespData5 7;
BA_ "GenSigSendType" SG_ 1590 SRR_RR_DiagRespData6 7;
BA_ "GenSigSendType" SG_ 1590 SRR_RR_DiagRespData7 7;
BA_ "GenSigSendType" SG_ 1591 SRR_RL_DiagRespData0 7;
BA_ "GenSigSendType" SG_ 1591 SRR_RL_DiagRespData1 7;
BA_ "GenSigSendType" SG_ 1591 SRR_RL_DiagRespData2 7;
BA_ "GenSigSendType" SG_ 1591 SRR_RL_DiagRespData3 7;
BA_ "GenSigSendType" SG_ 1591 SRR_RL_DiagRespData4 7;
BA_ "GenSigSendType" SG_ 1591 SRR_RL_DiagRespData5 7;
BA_ "GenSigSendType" SG_ 1591 SRR_RL_DiagRespData6 7;
BA_ "GenSigSendType" SG_ 1591 SRR_RL_DiagRespData7 7;
BA_ "GenSigSendType" SG_ 1600 ADAS_DiagRespData0 7;
BA_ "GenSigSendType" SG_ 1600 ADAS_DiagRespData1 7;
BA_ "GenSigSendType" SG_ 1600 ADAS_DiagRespData2 7;
BA_ "GenSigSendType" SG_ 1600 ADAS_DiagRespData3 7;
BA_ "GenSigSendType" SG_ 1600 ADAS_DiagRespData4 7;
BA_ "GenSigSendType" SG_ 1600 ADAS_DiagRespData5 7;
BA_ "GenSigSendType" SG_ 1600 ADAS_DiagRespData6 7;
BA_ "GenSigSendType" SG_ 1600 ADAS_DiagRespData7 7;
BA_ "GenSigSendType" SG_ 1679 YSS_DiagReqData0 7;
BA_ "GenSigSendType" SG_ 1679 YSS_DiagReqData1 7;
BA_ "GenSigSendType" SG_ 1679 YSS_DiagReqData2 7;
BA_ "GenSigSendType" SG_ 1679 YSS_DiagReqData3 7;
BA_ "GenSigSendType" SG_ 1679 YSS_DiagReqData4 7;
BA_ "GenSigSendType" SG_ 1679 YSS_DiagReqData5 7;
BA_ "GenSigSendType" SG_ 1679 YSS_DiagReqData6 7;
BA_ "GenSigSendType" SG_ 1679 YSS_DiagReqData7 7;
BA_ "GenSigSendType" SG_ 1701 MRGEN_DiagReqData0 7;
BA_ "GenSigSendType" SG_ 1701 MRGEN_DiagReqData1 7;
BA_ "GenSigSendType" SG_ 1701 MRGEN_DiagReqData2 7;
BA_ "GenSigSendType" SG_ 1701 MRGEN_DiagReqData3 7;
BA_ "GenSigSendType" SG_ 1701 MRGEN_DiagReqData4 7;
BA_ "GenSigSendType" SG_ 1701 MRGEN_DiagReqData5 7;
BA_ "GenSigSendType" SG_ 1701 MRGEN_DiagReqData6 7;
BA_ "GenSigSendType" SG_ 1701 MRGEN_DiagReqData7 7;
BA_ "GenSigSendType" SG_ 1702 SCAM_DiagReqData0 7;
BA_ "GenSigSendType" SG_ 1702 SCAM_DiagReqData1 7;
BA_ "GenSigSendType" SG_ 1702 SCAM_DiagReqData2 7;
BA_ "GenSigSendType" SG_ 1702 SCAM_DiagReqData3 7;
BA_ "GenSigSendType" SG_ 1702 SCAM_DiagReqData4 7;
BA_ "GenSigSendType" SG_ 1702 SCAM_DiagReqData5 7;
BA_ "GenSigSendType" SG_ 1702 SCAM_DiagReqData6 7;
BA_ "GenSigSendType" SG_ 1702 SCAM_DiagReqData7 7;
BA_ "GenSigSendType" SG_ 1703 RCU_DiagReqData0 7;
BA_ "GenSigSendType" SG_ 1703 RCU_DiagReqData1 7;
BA_ "GenSigSendType" SG_ 1703 RCU_DiagReqData2 7;
BA_ "GenSigSendType" SG_ 1703 RCU_DiagReqData3 7;
BA_ "GenSigSendType" SG_ 1703 RCU_DiagReqData4 7;
BA_ "GenSigSendType" SG_ 1703 RCU_DiagReqData5 7;
BA_ "GenSigSendType" SG_ 1703 RCU_DiagReqData6 7;
BA_ "GenSigSendType" SG_ 1703 RCU_DiagReqData7 7;
BA_ "GenSigSendType" SG_ 1704 EPS_DiagReqData0 7;
BA_ "GenSigSendType" SG_ 1704 EPS_DiagReqData1 7;
BA_ "GenSigSendType" SG_ 1704 EPS_DiagReqData2 7;
BA_ "GenSigSendType" SG_ 1704 EPS_DiagReqData3 7;
BA_ "GenSigSendType" SG_ 1704 EPS_DiagReqData4 7;
BA_ "GenSigSendType" SG_ 1704 EPS_DiagReqData5 7;
BA_ "GenSigSendType" SG_ 1704 EPS_DiagReqData6 7;
BA_ "GenSigSendType" SG_ 1704 EPS_DiagReqData7 7;
BA_ "GenSigSendType" SG_ 1705 IDB_DiagReqData0 7;
BA_ "GenSigSendType" SG_ 1705 IDB_DiagReqData1 7;
BA_ "GenSigSendType" SG_ 1705 IDB_DiagReqData2 7;
BA_ "GenSigSendType" SG_ 1705 IDB_DiagReqData3 7;
BA_ "GenSigSendType" SG_ 1705 IDB_DiagReqData4 7;
BA_ "GenSigSendType" SG_ 1705 IDB_DiagReqData5 7;
BA_ "GenSigSendType" SG_ 1705 IDB_DiagReqData6 7;
BA_ "GenSigSendType" SG_ 1705 IDB_DiagReqData7 7;
BA_ "GenSigSendType" SG_ 1706 AVAS_DiagReqData0 7;
BA_ "GenSigSendType" SG_ 1706 AVAS_DiagReqData1 7;
BA_ "GenSigSendType" SG_ 1706 AVAS_DiagReqData2 7;
BA_ "GenSigSendType" SG_ 1706 AVAS_DiagReqData3 7;
BA_ "GenSigSendType" SG_ 1706 AVAS_DiagReqData4 7;
BA_ "GenSigSendType" SG_ 1706 AVAS_DiagReqData5 7;
BA_ "GenSigSendType" SG_ 1706 AVAS_DiagReqData6 7;
BA_ "GenSigSendType" SG_ 1706 AVAS_DiagReqData7 7;
BA_ "GenSigSendType" SG_ 1708 VCU_DiagReqData0 7;
BA_ "GenSigSendType" SG_ 1708 VCU_DiagReqData1 7;
BA_ "GenSigSendType" SG_ 1708 VCU_DiagReqData2 7;
BA_ "GenSigSendType" SG_ 1708 VCU_DiagReqData3 7;
BA_ "GenSigSendType" SG_ 1708 VCU_DiagReqData4 7;
BA_ "GenSigSendType" SG_ 1708 VCU_DiagReqData5 7;
BA_ "GenSigSendType" SG_ 1708 VCU_DiagReqData6 7;
BA_ "GenSigSendType" SG_ 1708 VCU_DiagReqData7 7;
BA_ "GenSigSendType" SG_ 1716 SRR_FR_DiagReqData0 7;
BA_ "GenSigSendType" SG_ 1716 SRR_FR_DiagReqData1 7;
BA_ "GenSigSendType" SG_ 1716 SRR_FR_DiagReqData2 7;
BA_ "GenSigSendType" SG_ 1716 SRR_FR_DiagReqData3 7;
BA_ "GenSigSendType" SG_ 1716 SRR_FR_DiagReqData4 7;
BA_ "GenSigSendType" SG_ 1716 SRR_FR_DiagReqData5 7;
BA_ "GenSigSendType" SG_ 1716 SRR_FR_DiagReqData6 7;
BA_ "GenSigSendType" SG_ 1716 SRR_FR_DiagReqData7 7;
BA_ "GenSigSendType" SG_ 1717 SRR_FL_DiagReqData0 7;
BA_ "GenSigSendType" SG_ 1717 SRR_FL_DiagReqData1 7;
BA_ "GenSigSendType" SG_ 1717 SRR_FL_DiagReqData2 7;
BA_ "GenSigSendType" SG_ 1717 SRR_FL_DiagReqData3 7;
BA_ "GenSigSendType" SG_ 1717 SRR_FL_DiagReqData4 7;
BA_ "GenSigSendType" SG_ 1717 SRR_FL_DiagReqData5 7;
BA_ "GenSigSendType" SG_ 1717 SRR_FL_DiagReqData6 7;
BA_ "GenSigSendType" SG_ 1717 SRR_FL_DiagReqData7 7;
BA_ "GenSigSendType" SG_ 1718 SRR_RR_DiagReqData0 7;
BA_ "GenSigSendType" SG_ 1718 SRR_RR_DiagReqData1 7;
BA_ "GenSigSendType" SG_ 1718 SRR_RR_DiagReqData2 7;
BA_ "GenSigSendType" SG_ 1718 SRR_RR_DiagReqData3 7;
BA_ "GenSigSendType" SG_ 1718 SRR_RR_DiagReqData4 7;
BA_ "GenSigSendType" SG_ 1718 SRR_RR_DiagReqData5 7;
BA_ "GenSigSendType" SG_ 1718 SRR_RR_DiagReqData6 7;
BA_ "GenSigSendType" SG_ 1718 SRR_RR_DiagReqData7 7;
BA_ "GenSigSendType" SG_ 1719 SRR_RL_DiagReqData0 7;
BA_ "GenSigSendType" SG_ 1719 SRR_RL_DiagReqData1 7;
BA_ "GenSigSendType" SG_ 1719 SRR_RL_DiagReqData2 7;
BA_ "GenSigSendType" SG_ 1719 SRR_RL_DiagReqData3 7;
BA_ "GenSigSendType" SG_ 1719 SRR_RL_DiagReqData4 7;
BA_ "GenSigSendType" SG_ 1719 SRR_RL_DiagReqData5 7;
BA_ "GenSigSendType" SG_ 1719 SRR_RL_DiagReqData6 7;
BA_ "GenSigSendType" SG_ 1719 SRR_RL_DiagReqData7 7;
BA_ "GenSigSendType" SG_ 1728 ADAS_DiagReqData0 7;
BA_ "GenSigSendType" SG_ 1728 ADAS_DiagReqData1 7;
BA_ "GenSigSendType" SG_ 1728 ADAS_DiagReqData2 7;
BA_ "GenSigSendType" SG_ 1728 ADAS_DiagReqData3 7;
BA_ "GenSigSendType" SG_ 1728 ADAS_DiagReqData4 7;
BA_ "GenSigSendType" SG_ 1728 ADAS_DiagReqData5 7;
BA_ "GenSigSendType" SG_ 1728 ADAS_DiagReqData6 7;
BA_ "GenSigSendType" SG_ 1728 ADAS_DiagReqData7 7;
BA_ "GenSigSendType" SG_ 1775 DiagReqAllCANData0 7;
BA_ "GenSigSendType" SG_ 1775 DiagReqAllCANData1 7;
BA_ "GenSigSendType" SG_ 1775 DiagReqAllCANData2 7;
BA_ "GenSigSendType" SG_ 1775 DiagReqAllCANData3 7;
BA_ "GenSigSendType" SG_ 1775 DiagReqAllCANData4 7;
BA_ "GenSigSendType" SG_ 1775 DiagReqAllCANData5 7;
BA_ "GenSigSendType" SG_ 1775 DiagReqAllCANData6 7;
BA_ "GenSigSendType" SG_ 1775 DiagReqAllCANData7 7;
BA_ "GenSigSendType" SG_ 1791 DiagReqAllEcuData0 7;
BA_ "GenSigSendType" SG_ 1791 DiagReqAllEcuData1 7;
BA_ "GenSigSendType" SG_ 1791 DiagReqAllEcuData2 7;
BA_ "GenSigSendType" SG_ 1791 DiagReqAllEcuData3 7;
BA_ "GenSigSendType" SG_ 1791 DiagReqAllEcuData4 7;
BA_ "GenSigSendType" SG_ 1791 DiagReqAllEcuData5 7;
BA_ "GenSigSendType" SG_ 1791 DiagReqAllEcuData6 7;
BA_ "GenSigSendType" SG_ 1791 DiagReqAllEcuData7 7;
BA_ "GenSigSendType" SG_ 1817 SEED_CAN_Req11 7;
BA_ "GenSigSendType" SG_ 1827 SEED_CAN_Req13 7;
BA_ "GenSigSendType" SG_ 1829 SEED_CAN_Req14 7;
BA_ "GenSigSendType" SG_ 1831 SEED_CAN_Req15 7;
BA_ "GenSigSendType" SG_ 1960 EPS_XCP_CCPRespData0 7;
BA_ "GenSigSendType" SG_ 1960 EPS_XCP_CCPRespData1 7;
BA_ "GenSigSendType" SG_ 1960 EPS_XCP_CCPRespData2 7;
BA_ "GenSigSendType" SG_ 1960 EPS_XCP_CCPRespData3 7;
BA_ "GenSigSendType" SG_ 1960 EPS_XCP_CCPRespData4 7;
BA_ "GenSigSendType" SG_ 1960 EPS_XCP_CCPRespData5 7;
BA_ "GenSigSendType" SG_ 1960 EPS_XCP_CCPRespData6 7;
BA_ "GenSigSendType" SG_ 1960 EPS_XCP_CCPRespData7 7;
BA_ "GenSigSendType" SG_ 2007 EPS_XCP_CCPReqData0 7;
BA_ "GenSigSendType" SG_ 2007 EPS_XCP_CCPReqData1 7;
BA_ "GenSigSendType" SG_ 2007 EPS_XCP_CCPReqData2 7;
BA_ "GenSigSendType" SG_ 2007 EPS_XCP_CCPReqData3 7;
BA_ "GenSigSendType" SG_ 2007 EPS_XCP_CCPReqData4 7;
BA_ "GenSigSendType" SG_ 2007 EPS_XCP_CCPReqData5 7;
BA_ "GenSigSendType" SG_ 2007 EPS_XCP_CCPReqData6 7;
BA_ "GenSigSendType" SG_ 2007 EPS_XCP_CCPReqData7 7;
BA_ "GenSigSendType" SG_ 2015 Diag_Request_ECU_Data0 7;
BA_ "GenSigSendType" SG_ 2015 Diag_Request_ECU_Data1 7;
BA_ "GenSigSendType" SG_ 2015 Diag_Request_ECU_Data2 7;
BA_ "GenSigSendType" SG_ 2015 Diag_Request_ECU_Data3 7;
BA_ "GenSigSendType" SG_ 2015 Diag_Request_ECU_Data4 7;
BA_ "GenSigSendType" SG_ 2015 Diag_Request_ECU_Data5 7;
BA_ "GenSigSendType" SG_ 2015 Diag_Request_ECU_Data6 7;
BA_ "GenSigSendType" SG_ 2015 Diag_Request_ECU_Data7 7;
VAL_ 1039 YSS_Warning_Flag_1 0 "No Error" 1 "Error" ;
VAL_ 1039 YSS_Warning_Flag_2 0 "No Error" 1 "Error" ;
VAL_ 1039 YSS_Warning_Flag_3 0 "No Error" 1 "Error" ;
VAL_ 1039 YSS_Warning_Flag_4 0 "No Error" 1 "Error" ;
VAL_ 1039 YSS_Warning_Flag_5 0 "No Error" 1 "Error" ;
VAL_ 1039 YSS_Warning_Flag_6 0 "No Error" 1 "Error" ;
VAL_ 1039 YSS_Warning_Flag_7 0 "No Error" 1 "Error" ;
VAL_ 1039 YSS_Warning_Flag_8 0 "No Error" 1 "Error" ;
VAL_ 1039 YSS_Warning_Flag_9 0 "No Error" 1 "Error" ;
VAL_ 1039 YSS_Warning_Flag_10 0 "No Error" 1 "Error" ;
VAL_ 1039 YSS_Warning_Flag_11 0 "No Error" 1 "Error" ;
VAL_ 1039 YSS_Warning_Flag_12 0 "No Error" 1 "Error" ;
VAL_ 1059 AVAS_BatteryUnderVoltage 0 "Normal" 1 "Failure" ;
VAL_ 1059 AVAS_BatteryOverVoltage 0 "Normal" 1 "Failure" ;
VAL_ 1059 AVAS_VINInfoNotPrgm 0 "Normal" 1 "Failure" ;
VAL_ 1059 AVAS_AMPVoltSplDrvOperationFail 0 "Normal" 1 "Failure" ;
VAL_ 1059 AVAS_AMPIntFaultOverCurr 0 "Normal" 1 "Failure" ;
VAL_ 1059 AVAS_AMPInternalFaultDCError 0 "Normal" 1 "Failure" ;
VAL_ 1059 AVAS_AMPInternalFaultOverTemp 0 "Normal" 1 "Failure" ;
VAL_ 1059 AVAS_AMPInternalFaultClockError 0 "Normal" 1 "Failure" ;
VAL_ 1059 AVAS_SpkrMntPwrSwDrvHighFlt 0 "Normal" 1 "Failure" ;
VAL_ 1059 AVAS_SpkrMntPwrSwDrvLowFlt 0 "Normal" 1 "Failure" ;
VAL_ 1059 AVAS_InternalSpeakerOpen 0 "Normal" 1 "Failure" ;
VAL_ 1059 AVAS_ECUMalFlshOperationErr 0 "Normal" 1 "Failure" ;
VAL_ 1059 AVAS_ECUMalfunctionRamFailure 0 "Normal" 1 "Failure" ;
VAL_ 1059 AVAS_ECUMalEEPROMFailure 0 "Normal" 1 "Failure" ;
VAL_ 1059 AVAS_CANBusOff 0 "Normal" 1 "Failure" ;
VAL_ 1059 AVAS_LossCommVehicleSpeed 0 "Normal" 1 "Failure" ;
VAL_ 1059 AVAS_LossCommGearPosition 0 "Normal" 1 "Failure" ;
VAL_ 1059 AVAS_LossCommAVASCloseCmd 0 "Normal" 1 "Failure" ;
VAL_ 1061 ActualGearShiftPosition 0 "Initial State" 1 "R" 2 "N" 3 "D" 4 "P" 5 "Reserved" 6 "Reserved" 7 "Invalid" ;
VAL_ 1062 VCU_STAT_Terminal_BEV 0 "OFF(Comfort Enable)" 1 "ACC (Park)" 2 "ON (Driver Present)" 3 "Engine start (eMotor running)" 4 "SW Update OTA" 5 "Reserved" 6 "Reserved" 7 "Signal invalid" ;
VAL_ 1063 IPC_AVASCloseCmd 0 "OFF" 1 "ON" ;
VAL_ 1064 BCM_Keyfob_Leftcar 0 "None" 1 "Alert" ;
VAL_ 1064 TRMFitted 0 "Unsupported" 1 "Fitted" 2 "Not Fitted" 3 "SNA" ;
VAL_ 1072 ADAS_DMS_HapWarning 0 "Deactivation" 1 "Activation" ;
VAL_ 1074 MHU_FOTA_State 0 "INIT" 1 "NORMAL" 2 "FOTA FLASHING" 3 "FOTA-SUSPENDED" 4 "FAIL-SAFE-ERROR" 5 "SHUTDOWN" 6 "REMOTE DIAGNOSTICS" 7 "Invalid" ;
VAL_ 1095 MHU_Request_CarOFF 0 "Not Request" 1 "Request Car goes to OFF" 2 "Reserved" 3 "Signal Invalid" ;
VAL_ 1095 MHU_SET_ChildMode 0 "Child Mode OFF" 1 "Child mode ON" 2 "Reserved" 3 "Signal Invalid" ;
VAL_ 1095 MHU_SET_GameMode 0 "Game mode OFF" 1 "Game mode ON" 2 "Reserved" 3 "Signal Invalid" ;
VAL_ 1095 MHU_SET_KaraokeMode 0 "Karaoke mode OFF" 1 "Karaoke ON" 2 "Reserved" 3 "Signal Invalid" ;
VAL_ 1095 MHU_SET_WashMode 0 "Wash mode OFFt" 1 "Wash mode ON" 2 "Reserved" 3 "Signal Invalid" ;
VAL_ 1095 MHU_SET_StopMode 0 "Creep" 1 "Hold" 2 "Roll" 3 "Signal Invalid" ;
VAL_ 1191 RCU_DAA_NoOpDoorOpen 0 "None" 1 "Alert" ;
VAL_ 1191 RCU_EHandBrk_fault 0 "None" 1 "Alert" ;
VAL_ 1191 RCU_EOL_NotDone 0 "None" 1 "Alert" ;
VAL_ 1191 RCU_ECD_RWU_active 0 "None" 1 "Alert" ;
VAL_ 1191 RCU_ParkOnSteepInclination 0 "None" 1 "Alert" ;
VAL_ 1191 RCU_BrkForceNotEnough 0 "None" 1 "Alert" ;
VAL_ 1191 RCU_ReleaseEPB_Wo_PressBrk 0 "None" 1 "Alert" ;
VAL_ 1191 RCU_ParkBrkApplied 0 "None" 1 "Alert" ;
VAL_ 1191 RCU_Swch_Mafnc 0 "None" 1 "Alert" ;
VAL_ 1191 RCU_DAA_NoOpBeltUnbuckled 0 "None" 1 "Alert" ;
VAL_ 1191 RCU_RollerBenchMode 0 "None" 1 "Alert" ;
VAL_ 1191 RCU_EPB_ParkLampState 0 "No Indication" 1 "Durable" 2 "Bilinking 1Hz" 3 "Blinking 3Hz" ;
VAL_ 1191 RCU_EPB_WarnLampState 0 "No Indication" 1 "Durable" 2 "Bilinking 1Hz" 3 "Blinking 3Hz" ;
VAL_ 1191 RCU_WflagRes36 0 "None" 1 "Alert" ;
VAL_ 1191 RCU_WflagRes37 0 "None" 1 "Alert" ;
VAL_ 1191 RCU_WflagRes38 0 "None" 1 "Alert" ;
VAL_ 1191 RCU_WflagRes39 0 "None" 1 "Alert" ;
VAL_ 1191 RCU_WflagRes40 0 "None" 1 "Alert" ;
VAL_ 1191 RCU_WflagRes41 0 "None" 1 "Alert" ;
VAL_ 1191 RCU_WflagRes42 0 "None" 1 "Alert" ;
VAL_ 1191 RCU_WflagRes43 0 "None" 1 "Alert" ;
VAL_ 1191 RCU_WflagRes44 0 "None" 1 "Alert" ;
VAL_ 1191 RCU_WflagRes45 0 "None" 1 "Alert" ;
VAL_ 1191 RCU_WflagRes46 0 "None" 1 "Alert" ;
VAL_ 1191 RCU_WflagRes47 0 "None" 1 "Alert" ;
VAL_ 1192 EPS_Malfunction 0 "No Error" 1 "Error" ;
VAL_ 1192 EPS_Reduced 0 "No Error" 1 "Error" ;
VAL_ 1192 EPS_Overheat 0 "No Error" 1 "Error" ;
VAL_ 1192 EPS_NotReady 0 "No Error" 1 "Error" ;
VAL_ 1192 EPS_Warning_Flag_5 0 "No Error" 1 "Error" ;
VAL_ 1192 EPS_Warning_Flag_6 0 "No Error" 1 "Error" ;
VAL_ 1192 EPS_Warning_Flag_7 0 "No Error" 1 "Error" ;
VAL_ 1192 EPS_Warning_Flag_8 0 "No Error" 1 "Error" ;
VAL_ 1192 EPS_Warning_Flag_9 0 "No Error" 1 "Error" ;
VAL_ 1192 EPS_Warning_Flag_10 0 "No Error" 1 "Error" ;
VAL_ 1192 EPS_Warning_Flag_11 0 "No Error" 1 "Error" ;
VAL_ 1192 EPS_Warning_Flag_12 0 "No Error" 1 "Error" ;
VAL_ 1193 IDB_ESC_fault 0 "No Error" 1 "Error" ;
VAL_ 1193 IDB_ABS_fault 0 "No Error" 1 "Error" ;
VAL_ 1193 IDB_BrkLowFluid 0 "No Error" 1 "Error" ;
VAL_ 1193 IDB_BrkSysFault 0 "No Error" 1 "Error" ;
VAL_ 1193 IDB_fault 0 "No Error" 1 "Error" ;
VAL_ 1193 IDB_HydraulicBrkAssist_Fault 0 "No Error" 1 "Error" ;
VAL_ 1193 IDB_HAS_Fault 0 "No Error" 1 "Error" ;
VAL_ 1193 IDB_TSM_Fault 0 "No Error" 1 "Error" ;
